VERSION ""

NS_ :

BS_:

BU_: RADAR XXX

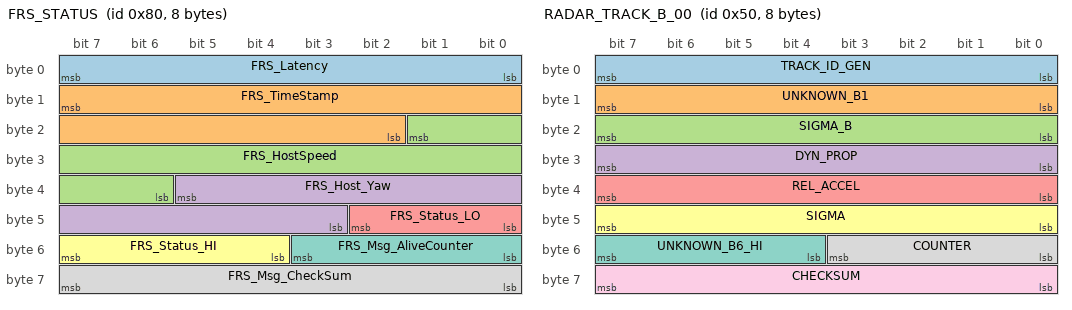
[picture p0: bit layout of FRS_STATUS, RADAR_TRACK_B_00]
BO_ 128 FRS_STATUS: 8 RADAR
 SG_ FRS_Latency : 7|8@0+ (0.5,0) [0|127] "ms" XXX
 SG_ FRS_TimeStamp : 15|14@0+ (1.0077,0) [0|16510] "s" XXX
 SG_ FRS_HostSpeed : 17|12@0+ (0.0243,-19.3) [0|80] "m/s" XXX
 SG_ FRS_Host_Yaw : 37|11@0+ (0.1,-102.4) [-102.4|102.3] "deg/s" XXX
 SG_ FRS_Status_LO : 42|3@0+ (1,0) [0|7] "" XXX
 SG_ FRS_Status_HI : 55|4@0+ (1,0) [0|15] "" XXX
 SG_ FRS_Msg_AliveCounter : 51|4@0+ (1,0) [0|15] "" XXX
 SG_ FRS_Msg_CheckSum : 63|8@0+ (1,0) [0|255] "" XXX

BO_ 32 RADAR_TRACK_A_00: 8 RADAR
 SG_ REL_SPEED : 7|8@0+ (0.7874,-100.47) [-100.5|99.9] "m/s" XXX
 SG_ UNKNOWN_B1 : 15|8@0+ (1,0) [0|255] "" XXX
 SG_ UNKNOWN_B2 : 23|8@0+ (1,0) [0|255] "" XXX
 SG_ LAT_POS : 12|13@0+ (0.015625,-64) [-64|64] "m" XXX
 SG_ DISTANCE : 31|16@0+ (0.00382813,-3.4) [0|247] "m" XXX
 SG_ LAT_SPEED : 47|8@0+ (0.7874,-100.79) [-100.8|99.6] "m/s" XXX
 SG_ UNKNOWN_B6_HI : 55|4@0+ (1,0) [0|15] "" XXX
 SG_ COUNTER : 51|4@0+ (1,0) [0|15] "" XXX
 SG_ CHECKSUM : 63|8@0+ (1,0) [0|255] "" XXX

BO_ 33 RADAR_TRACK_A_01: 8 RADAR
 SG_ REL_SPEED : 7|8@0+ (0.7874,-100.47) [-100.5|99.9] "m/s" XXX
 SG_ UNKNOWN_B1 : 15|8@0+ (1,0) [0|255] "" XXX
 SG_ UNKNOWN_B2 : 23|8@0+ (1,0) [0|255] "" XXX
 SG_ LAT_POS : 12|13@0+ (0.015625,-64) [-64|64] "m" XXX
 SG_ DISTANCE : 31|16@0+ (0.00382813,-3.4) [0|247] "m" XXX
 SG_ LAT_SPEED : 47|8@0+ (0.7874,-100.79) [-100.8|99.6] "m/s" XXX
 SG_ UNKNOWN_B6_HI : 55|4@0+ (1,0) [0|15] "" XXX
 SG_ COUNTER : 51|4@0+ (1,0) [0|15] "" XXX
 SG_ CHECKSUM : 63|8@0+ (1,0) [0|255] "" XXX

BO_ 34 RADAR_TRACK_A_02: 8 RADAR
 SG_ REL_SPEED : 7|8@0+ (0.7874,-100.47) [-100.5|99.9] "m/s" XXX
 SG_ UNKNOWN_B1 : 15|8@0+ (1,0) [0|255] "" XXX
 SG_ UNKNOWN_B2 : 23|8@0+ (1,0) [0|255] "" XXX
 SG_ LAT_POS : 12|13@0+ (0.015625,-64) [-64|64] "m" XXX
 SG_ DISTANCE : 31|16@0+ (0.00382813,-3.4) [0|247] "m" XXX
 SG_ LAT_SPEED : 47|8@0+ (0.7874,-100.79) [-100.8|99.6] "m/s" XXX
 SG_ UNKNOWN_B6_HI : 55|4@0+ (1,0) [0|15] "" XXX
 SG_ COUNTER : 51|4@0+ (1,0) [0|15] "" XXX
 SG_ CHECKSUM : 63|8@0+ (1,0) [0|255] "" XXX

BO_ 35 RADAR_TRACK_A_03: 8 RADAR
 SG_ REL_SPEED : 7|8@0+ (0.7874,-100.47) [-100.5|99.9] "m/s" XXX
 SG_ UNKNOWN_B1 : 15|8@0+ (1,0) [0|255] "" XXX
 SG_ UNKNOWN_B2 : 23|8@0+ (1,0) [0|255] "" XXX
 SG_ LAT_POS : 12|13@0+ (0.015625,-64) [-64|64] "m" XXX
 SG_ DISTANCE : 31|16@0+ (0.00382813,-3.4) [0|247] "m" XXX
 SG_ LAT_SPEED : 47|8@0+ (0.7874,-100.79) [-100.8|99.6] "m/s" XXX
 SG_ UNKNOWN_B6_HI : 55|4@0+ (1,0) [0|15] "" XXX
 SG_ COUNTER : 51|4@0+ (1,0) [0|15] "" XXX
 SG_ CHECKSUM : 63|8@0+ (1,0) [0|255] "" XXX

BO_ 36 RADAR_TRACK_A_04: 8 RADAR
 SG_ REL_SPEED : 7|8@0+ (0.7874,-100.47) [-100.5|99.9] "m/s" XXX
 SG_ UNKNOWN_B1 : 15|8@0+ (1,0) [0|255] "" XXX
 SG_ UNKNOWN_B2 : 23|8@0+ (1,0) [0|255] "" XXX
 SG_ LAT_POS : 12|13@0+ (0.015625,-64) [-64|64] "m" XXX
 SG_ DISTANCE : 31|16@0+ (0.00382813,-3.4) [0|247] "m" XXX
 SG_ LAT_SPEED : 47|8@0+ (0.7874,-100.79) [-100.8|99.6] "m/s" XXX
 SG_ UNKNOWN_B6_HI : 55|4@0+ (1,0) [0|15] "" XXX
 SG_ COUNTER : 51|4@0+ (1,0) [0|15] "" XXX
 SG_ CHECKSUM : 63|8@0+ (1,0) [0|255] "" XXX

BO_ 37 RADAR_TRACK_A_05: 8 RADAR
 SG_ REL_SPEED : 7|8@0+ (0.7874,-100.47) [-100.5|99.9] "m/s" XXX
 SG_ UNKNOWN_B1 : 15|8@0+ (1,0) [0|255] "" XXX
 SG_ UNKNOWN_B2 : 23|8@0+ (1,0) [0|255] "" XXX
 SG_ LAT_POS : 12|13@0+ (0.015625,-64) [-64|64] "m" XXX
 SG_ DISTANCE : 31|16@0+ (0.00382813,-3.4) [0|247] "m" XXX
 SG_ LAT_SPEED : 47|8@0+ (0.7874,-100.79) [-100.8|99.6] "m/s" XXX
 SG_ UNKNOWN_B6_HI : 55|4@0+ (1,0) [0|15] "" XXX
 SG_ COUNTER : 51|4@0+ (1,0) [0|15] "" XXX
 SG_ CHECKSUM : 63|8@0+ (1,0) [0|255] "" XXX

BO_ 38 RADAR_TRACK_A_06: 8 RADAR
 SG_ REL_SPEED : 7|8@0+ (0.7874,-100.47) [-100.5|99.9] "m/s" XXX
 SG_ UNKNOWN_B1 : 15|8@0+ (1,0) [0|255] "" XXX
 SG_ UNKNOWN_B2 : 23|8@0+ (1,0) [0|255] "" XXX
 SG_ LAT_POS : 12|13@0+ (0.015625,-64) [-64|64] "m" XXX
 SG_ DISTANCE : 31|16@0+ (0.00382813,-3.4) [0|247] "m" XXX
 SG_ LAT_SPEED : 47|8@0+ (0.7874,-100.79) [-100.8|99.6] "m/s" XXX
 SG_ UNKNOWN_B6_HI : 55|4@0+ (1,0) [0|15] "" XXX
 SG_ COUNTER : 51|4@0+ (1,0) [0|15] "" XXX
 SG_ CHECKSUM : 63|8@0+ (1,0) [0|255] "" XXX

BO_ 39 RADAR_TRACK_A_07: 8 RADAR
 SG_ REL_SPEED : 7|8@0+ (0.7874,-100.47) [-100.5|99.9] "m/s" XXX
 SG_ UNKNOWN_B1 : 15|8@0+ (1,0) [0|255] "" XXX
 SG_ UNKNOWN_B2 : 23|8@0+ (1,0) [0|255] "" XXX
 SG_ LAT_POS : 12|13@0+ (0.015625,-64) [-64|64] "m" XXX
 SG_ DISTANCE : 31|16@0+ (0.00382813,-3.4) [0|247] "m" XXX
 SG_ LAT_SPEED : 47|8@0+ (0.7874,-100.79) [-100.8|99.6] "m/s" XXX
 SG_ UNKNOWN_B6_HI : 55|4@0+ (1,0) [0|15] "" XXX
 SG_ COUNTER : 51|4@0+ (1,0) [0|15] "" XXX
 SG_ CHECKSUM : 63|8@0+ (1,0) [0|255] "" XXX

BO_ 40 RADAR_TRACK_A_08: 8 RADAR
 SG_ REL_SPEED : 7|8@0+ (0.7874,-100.47) [-100.5|99.9] "m/s" XXX
 SG_ UNKNOWN_B1 : 15|8@0+ (1,0) [0|255] "" XXX
 SG_ UNKNOWN_B2 : 23|8@0+ (1,0) [0|255] "" XXX
 SG_ LAT_POS : 12|13@0+ (0.015625,-64) [-64|64] "m" XXX
 SG_ DISTANCE : 31|16@0+ (0.00382813,-3.4) [0|247] "m" XXX
 SG_ LAT_SPEED : 47|8@0+ (0.7874,-100.79) [-100.8|99.6] "m/s" XXX
 SG_ UNKNOWN_B6_HI : 55|4@0+ (1,0) [0|15] "" XXX
 SG_ COUNTER : 51|4@0+ (1,0) [0|15] "" XXX
 SG_ CHECKSUM : 63|8@0+ (1,0) [0|255] "" XXX

BO_ 41 RADAR_TRACK_A_09: 8 RADAR
 SG_ REL_SPEED : 7|8@0+ (0.7874,-100.47) [-100.5|99.9] "m/s" XXX
 SG_ UNKNOWN_B1 : 15|8@0+ (1,0) [0|255] "" XXX
 SG_ UNKNOWN_B2 : 23|8@0+ (1,0) [0|255] "" XXX
 SG_ LAT_POS : 12|13@0+ (0.015625,-64) [-64|64] "m" XXX
 SG_ DISTANCE : 31|16@0+ (0.00382813,-3.4) [0|247] "m" XXX
 SG_ LAT_SPEED : 47|8@0+ (0.7874,-100.79) [-100.8|99.6] "m/s" XXX
 SG_ UNKNOWN_B6_HI : 55|4@0+ (1,0) [0|15] "" XXX
 SG_ COUNTER : 51|4@0+ (1,0) [0|15] "" XXX
 SG_ CHECKSUM : 63|8@0+ (1,0) [0|255] "" XXX

BO_ 42 RADAR_TRACK_A_10: 8 RADAR
 SG_ REL_SPEED : 7|8@0+ (0.7874,-100.47) [-100.5|99.9] "m/s" XXX
 SG_ UNKNOWN_B1 : 15|8@0+ (1,0) [0|255] "" XXX
 SG_ UNKNOWN_B2 : 23|8@0+ (1,0) [0|255] "" XXX
 SG_ LAT_POS : 12|13@0+ (0.015625,-64) [-64|64] "m" XXX
 SG_ DISTANCE : 31|16@0+ (0.00382813,-3.4) [0|247] "m" XXX
 SG_ LAT_SPEED : 47|8@0+ (0.7874,-100.79) [-100.8|99.6] "m/s" XXX
 SG_ UNKNOWN_B6_HI : 55|4@0+ (1,0) [0|15] "" XXX
 SG_ COUNTER : 51|4@0+ (1,0) [0|15] "" XXX
 SG_ CHECKSUM : 63|8@0+ (1,0) [0|255] "" XXX

BO_ 43 RADAR_TRACK_A_11: 8 RADAR
 SG_ REL_SPEED : 7|8@0+ (0.7874,-100.47) [-100.5|99.9] "m/s" XXX
 SG_ UNKNOWN_B1 : 15|8@0+ (1,0) [0|255] "" XXX
 SG_ UNKNOWN_B2 : 23|8@0+ (1,0) [0|255] "" XXX
 SG_ LAT_POS : 12|13@0+ (0.015625,-64) [-64|64] "m" XXX
 SG_ DISTANCE : 31|16@0+ (0.00382813,-3.4) [0|247] "m" XXX
 SG_ LAT_SPEED : 47|8@0+ (0.7874,-100.79) [-100.8|99.6] "m/s" XXX
 SG_ UNKNOWN_B6_HI : 55|4@0+ (1,0) [0|15] "" XXX
 SG_ COUNTER : 51|4@0+ (1,0) [0|15] "" XXX
 SG_ CHECKSUM : 63|8@0+ (1,0) [0|255] "" XXX

BO_ 44 RADAR_TRACK_A_12: 8 RADAR
 SG_ REL_SPEED : 7|8@0+ (0.7874,-100.47) [-100.5|99.9] "m/s" XXX
 SG_ UNKNOWN_B1 : 15|8@0+ (1,0) [0|255] "" XXX
 SG_ UNKNOWN_B2 : 23|8@0+ (1,0) [0|255] "" XXX
 SG_ LAT_POS : 12|13@0+ (0.015625,-64) [-64|64] "m" XXX
 SG_ DISTANCE : 31|16@0+ (0.00382813,-3.4) [0|247] "m" XXX
 SG_ LAT_SPEED : 47|8@0+ (0.7874,-100.79) [-100.8|99.6] "m/s" XXX
 SG_ UNKNOWN_B6_HI : 55|4@0+ (1,0) [0|15] "" XXX
 SG_ COUNTER : 51|4@0+ (1,0) [0|15] "" XXX
 SG_ CHECKSUM : 63|8@0+ (1,0) [0|255] "" XXX

BO_ 45 RADAR_TRACK_A_13: 8 RADAR
 SG_ REL_SPEED : 7|8@0+ (0.7874,-100.47) [-100.5|99.9] "m/s" XXX
 SG_ UNKNOWN_B1 : 15|8@0+ (1,0) [0|255] "" XXX
 SG_ UNKNOWN_B2 : 23|8@0+ (1,0) [0|255] "" XXX
 SG_ LAT_POS : 12|13@0+ (0.015625,-64) [-64|64] "m" XXX
 SG_ DISTANCE : 31|16@0+ (0.00382813,-3.4) [0|247] "m" XXX
 SG_ LAT_SPEED : 47|8@0+ (0.7874,-100.79) [-100.8|99.6] "m/s" XXX
 SG_ UNKNOWN_B6_HI : 55|4@0+ (1,0) [0|15] "" XXX
 SG_ COUNTER : 51|4@0+ (1,0) [0|15] "" XXX
 SG_ CHECKSUM : 63|8@0+ (1,0) [0|255] "" XXX

BO_ 46 RADAR_TRACK_A_14: 8 RADAR
 SG_ REL_SPEED : 7|8@0+ (0.7874,-100.47) [-100.5|99.9] "m/s" XXX
 SG_ UNKNOWN_B1 : 15|8@0+ (1,0) [0|255] "" XXX
 SG_ UNKNOWN_B2 : 23|8@0+ (1,0) [0|255] "" XXX
 SG_ LAT_POS : 12|13@0+ (0.015625,-64) [-64|64] "m" XXX
 SG_ DISTANCE : 31|16@0+ (0.00382813,-3.4) [0|247] "m" XXX
 SG_ LAT_SPEED : 47|8@0+ (0.7874,-100.79) [-100.8|99.6] "m/s" XXX
 SG_ UNKNOWN_B6_HI : 55|4@0+ (1,0) [0|15] "" XXX
 SG_ COUNTER : 51|4@0+ (1,0) [0|15] "" XXX
 SG_ CHECKSUM : 63|8@0+ (1,0) [0|255] "" XXX

BO_ 47 RADAR_TRACK_A_15: 8 RADAR
 SG_ REL_SPEED : 7|8@0+ (0.7874,-100.47) [-100.5|99.9] "m/s" XXX
 SG_ UNKNOWN_B1 : 15|8@0+ (1,0) [0|255] "" XXX
 SG_ UNKNOWN_B2 : 23|8@0+ (1,0) [0|255] "" XXX
 SG_ LAT_POS : 12|13@0+ (0.015625,-64) [-64|64] "m" XXX
 SG_ DISTANCE : 31|16@0+ (0.00382813,-3.4) [0|247] "m" XXX
 SG_ LAT_SPEED : 47|8@0+ (0.7874,-100.79) [-100.8|99.6] "m/s" XXX
 SG_ UNKNOWN_B6_HI : 55|4@0+ (1,0) [0|15] "" XXX
 SG_ COUNTER : 51|4@0+ (1,0) [0|15] "" XXX
 SG_ CHECKSUM : 63|8@0+ (1,0) [0|255] "" XXX

BO_ 48 RADAR_TRACK_A_16: 8 RADAR
 SG_ REL_SPEED : 7|8@0+ (0.7874,-100.47) [-100.5|99.9] "m/s" XXX
 SG_ UNKNOWN_B1 : 15|8@0+ (1,0) [0|255] "" XXX
 SG_ UNKNOWN_B2 : 23|8@0+ (1,0) [0|255] "" XXX
 SG_ LAT_POS : 12|13@0+ (0.015625,-64) [-64|64] "m" XXX
 SG_ DISTANCE : 31|16@0+ (0.00382813,-3.4) [0|247] "m" XXX
 SG_ LAT_SPEED : 47|8@0+ (0.7874,-100.79) [-100.8|99.6] "m/s" XXX
 SG_ UNKNOWN_B6_HI : 55|4@0+ (1,0) [0|15] "" XXX
 SG_ COUNTER : 51|4@0+ (1,0) [0|15] "" XXX
 SG_ CHECKSUM : 63|8@0+ (1,0) [0|255] "" XXX

BO_ 49 RADAR_TRACK_A_17: 8 RADAR
 SG_ REL_SPEED : 7|8@0+ (0.7874,-100.47) [-100.5|99.9] "m/s" XXX
 SG_ UNKNOWN_B1 : 15|8@0+ (1,0) [0|255] "" XXX
 SG_ UNKNOWN_B2 : 23|8@0+ (1,0) [0|255] "" XXX
 SG_ LAT_POS : 12|13@0+ (0.015625,-64) [-64|64] "m" XXX
 SG_ DISTANCE : 31|16@0+ (0.00382813,-3.4) [0|247] "m" XXX
 SG_ LAT_SPEED : 47|8@0+ (0.7874,-100.79) [-100.8|99.6] "m/s" XXX
 SG_ UNKNOWN_B6_HI : 55|4@0+ (1,0) [0|15] "" XXX
 SG_ COUNTER : 51|4@0+ (1,0) [0|15] "" XXX
 SG_ CHECKSUM : 63|8@0+ (1,0) [0|255] "" XXX

BO_ 50 RADAR_TRACK_A_18: 8 RADAR
 SG_ REL_SPEED : 7|8@0+ (0.7874,-100.47) [-100.5|99.9] "m/s" XXX
 SG_ UNKNOWN_B1 : 15|8@0+ (1,0) [0|255] "" XXX
 SG_ UNKNOWN_B2 : 23|8@0+ (1,0) [0|255] "" XXX
 SG_ LAT_POS : 12|13@0+ (0.015625,-64) [-64|64] "m" XXX
 SG_ DISTANCE : 31|16@0+ (0.00382813,-3.4) [0|247] "m" XXX
 SG_ LAT_SPEED : 47|8@0+ (0.7874,-100.79) [-100.8|99.6] "m/s" XXX
 SG_ UNKNOWN_B6_HI : 55|4@0+ (1,0) [0|15] "" XXX
 SG_ COUNTER : 51|4@0+ (1,0) [0|15] "" XXX
 SG_ CHECKSUM : 63|8@0+ (1,0) [0|255] "" XXX

BO_ 51 RADAR_TRACK_A_19: 8 RADAR
 SG_ REL_SPEED : 7|8@0+ (0.7874,-100.47) [-100.5|99.9] "m/s" XXX
 SG_ UNKNOWN_B1 : 15|8@0+ (1,0) [0|255] "" XXX
 SG_ UNKNOWN_B2 : 23|8@0+ (1,0) [0|255] "" XXX
 SG_ LAT_POS : 12|13@0+ (0.015625,-64) [-64|64] "m" XXX
 SG_ DISTANCE : 31|16@0+ (0.00382813,-3.4) [0|247] "m" XXX
 SG_ LAT_SPEED : 47|8@0+ (0.7874,-100.79) [-100.8|99.6] "m/s" XXX
 SG_ UNKNOWN_B6_HI : 55|4@0+ (1,0) [0|15] "" XXX
 SG_ COUNTER : 51|4@0+ (1,0) [0|15] "" XXX
 SG_ CHECKSUM : 63|8@0+ (1,0) [0|255] "" XXX

BO_ 52 RADAR_TRACK_A_20: 8 RADAR
 SG_ REL_SPEED : 7|8@0+ (0.7874,-100.47) [-100.5|99.9] "m/s" XXX
 SG_ UNKNOWN_B1 : 15|8@0+ (1,0) [0|255] "" XXX
 SG_ UNKNOWN_B2 : 23|8@0+ (1,0) [0|255] "" XXX
 SG_ LAT_POS : 12|13@0+ (0.015625,-64) [-64|64] "m" XXX
 SG_ DISTANCE : 31|16@0+ (0.00382813,-3.4) [0|247] "m" XXX
 SG_ LAT_SPEED : 47|8@0+ (0.7874,-100.79) [-100.8|99.6] "m/s" XXX
 SG_ UNKNOWN_B6_HI : 55|4@0+ (1,0) [0|15] "" XXX
 SG_ COUNTER : 51|4@0+ (1,0) [0|15] "" XXX
 SG_ CHECKSUM : 63|8@0+ (1,0) [0|255] "" XXX

BO_ 53 RADAR_TRACK_A_21: 8 RADAR
 SG_ REL_SPEED : 7|8@0+ (0.7874,-100.47) [-100.5|99.9] "m/s" XXX
 SG_ UNKNOWN_B1 : 15|8@0+ (1,0) [0|255] "" XXX
 SG_ UNKNOWN_B2 : 23|8@0+ (1,0) [0|255] "" XXX
 SG_ LAT_POS : 12|13@0+ (0.015625,-64) [-64|64] "m" XXX
 SG_ DISTANCE : 31|16@0+ (0.00382813,-3.4) [0|247] "m" XXX
 SG_ LAT_SPEED : 47|8@0+ (0.7874,-100.79) [-100.8|99.6] "m/s" XXX
 SG_ UNKNOWN_B6_HI : 55|4@0+ (1,0) [0|15] "" XXX
 SG_ COUNTER : 51|4@0+ (1,0) [0|15] "" XXX
 SG_ CHECKSUM : 63|8@0+ (1,0) [0|255] "" XXX

BO_ 54 RADAR_TRACK_A_22: 8 RADAR
 SG_ REL_SPEED : 7|8@0+ (0.7874,-100.47) [-100.5|99.9] "m/s" XXX
 SG_ UNKNOWN_B1 : 15|8@0+ (1,0) [0|255] "" XXX
 SG_ UNKNOWN_B2 : 23|8@0+ (1,0) [0|255] "" XXX
 SG_ LAT_POS : 12|13@0+ (0.015625,-64) [-64|64] "m" XXX
 SG_ DISTANCE : 31|16@0+ (0.00382813,-3.4) [0|247] "m" XXX
 SG_ LAT_SPEED : 47|8@0+ (0.7874,-100.79) [-100.8|99.6] "m/s" XXX
 SG_ UNKNOWN_B6_HI : 55|4@0+ (1,0) [0|15] "" XXX
 SG_ COUNTER : 51|4@0+ (1,0) [0|15] "" XXX
 SG_ CHECKSUM : 63|8@0+ (1,0) [0|255] "" XXX

BO_ 55 RADAR_TRACK_A_23: 8 RADAR
 SG_ REL_SPEED : 7|8@0+ (0.7874,-100.47) [-100.5|99.9] "m/s" XXX
 SG_ UNKNOWN_B1 : 15|8@0+ (1,0) [0|255] "" XXX
 SG_ UNKNOWN_B2 : 23|8@0+ (1,0) [0|255] "" XXX
 SG_ LAT_POS : 12|13@0+ (0.015625,-64) [-64|64] "m" XXX
 SG_ DISTANCE : 31|16@0+ (0.00382813,-3.4) [0|247] "m" XXX
 SG_ LAT_SPEED : 47|8@0+ (0.7874,-100.79) [-100.8|99.6] "m/s" XXX
 SG_ UNKNOWN_B6_HI : 55|4@0+ (1,0) [0|15] "" XXX
 SG_ COUNTER : 51|4@0+ (1,0) [0|15] "" XXX
 SG_ CHECKSUM : 63|8@0+ (1,0) [0|255] "" XXX

BO_ 56 RADAR_TRACK_A_24: 8 RADAR
 SG_ REL_SPEED : 7|8@0+ (0.7874,-100.47) [-100.5|99.9] "m/s" XXX
 SG_ UNKNOWN_B1 : 15|8@0+ (1,0) [0|255] "" XXX
 SG_ UNKNOWN_B2 : 23|8@0+ (1,0) [0|255] "" XXX
 SG_ LAT_POS : 12|13@0+ (0.015625,-64) [-64|64] "m" XXX
 SG_ DISTANCE : 31|16@0+ (0.00382813,-3.4) [0|247] "m" XXX
 SG_ LAT_SPEED : 47|8@0+ (0.7874,-100.79) [-100.8|99.6] "m/s" XXX
 SG_ UNKNOWN_B6_HI : 55|4@0+ (1,0) [0|15] "" XXX
 SG_ COUNTER : 51|4@0+ (1,0) [0|15] "" XXX
 SG_ CHECKSUM : 63|8@0+ (1,0) [0|255] "" XXX

BO_ 57 RADAR_TRACK_A_25: 8 RADAR
 SG_ REL_SPEED : 7|8@0+ (0.7874,-100.47) [-100.5|99.9] "m/s" XXX
 SG_ UNKNOWN_B1 : 15|8@0+ (1,0) [0|255] "" XXX
 SG_ UNKNOWN_B2 : 23|8@0+ (1,0) [0|255] "" XXX
 SG_ LAT_POS : 12|13@0+ (0.015625,-64) [-64|64] "m" XXX
 SG_ DISTANCE : 31|16@0+ (0.00382813,-3.4) [0|247] "m" XXX
 SG_ LAT_SPEED : 47|8@0+ (0.7874,-100.79) [-100.8|99.6] "m/s" XXX
 SG_ UNKNOWN_B6_HI : 55|4@0+ (1,0) [0|15] "" XXX
 SG_ COUNTER : 51|4@0+ (1,0) [0|15] "" XXX
 SG_ CHECKSUM : 63|8@0+ (1,0) [0|255] "" XXX

BO_ 58 RADAR_TRACK_A_26: 8 RADAR
 SG_ REL_SPEED : 7|8@0+ (0.7874,-100.47) [-100.5|99.9] "m/s" XXX
 SG_ UNKNOWN_B1 : 15|8@0+ (1,0) [0|255] "" XXX
 SG_ UNKNOWN_B2 : 23|8@0+ (1,0) [0|255] "" XXX
 SG_ LAT_POS : 12|13@0+ (0.015625,-64) [-64|64] "m" XXX
 SG_ DISTANCE : 31|16@0+ (0.00382813,-3.4) [0|247] "m" XXX
 SG_ LAT_SPEED : 47|8@0+ (0.7874,-100.79) [-100.8|99.6] "m/s" XXX
 SG_ UNKNOWN_B6_HI : 55|4@0+ (1,0) [0|15] "" XXX
 SG_ COUNTER : 51|4@0+ (1,0) [0|15] "" XXX
 SG_ CHECKSUM : 63|8@0+ (1,0) [0|255] "" XXX

BO_ 59 RADAR_TRACK_A_27: 8 RADAR
 SG_ REL_SPEED : 7|8@0+ (0.7874,-100.47) [-100.5|99.9] "m/s" XXX
 SG_ UNKNOWN_B1 : 15|8@0+ (1,0) [0|255] "" XXX
 SG_ UNKNOWN_B2 : 23|8@0+ (1,0) [0|255] "" XXX
 SG_ LAT_POS : 12|13@0+ (0.015625,-64) [-64|64] "m" XXX
 SG_ DISTANCE : 31|16@0+ (0.00382813,-3.4) [0|247] "m" XXX
 SG_ LAT_SPEED : 47|8@0+ (0.7874,-100.79) [-100.8|99.6] "m/s" XXX
 SG_ UNKNOWN_B6_HI : 55|4@0+ (1,0) [0|15] "" XXX
 SG_ COUNTER : 51|4@0+ (1,0) [0|15] "" XXX
 SG_ CHECKSUM : 63|8@0+ (1,0) [0|255] "" XXX

BO_ 60 RADAR_TRACK_A_28: 8 RADAR
 SG_ REL_SPEED : 7|8@0+ (0.7874,-100.47) [-100.5|99.9] "m/s" XXX
 SG_ UNKNOWN_B1 : 15|8@0+ (1,0) [0|255] "" XXX
 SG_ UNKNOWN_B2 : 23|8@0+ (1,0) [0|255] "" XXX
 SG_ LAT_POS : 12|13@0+ (0.015625,-64) [-64|64] "m" XXX
 SG_ DISTANCE : 31|16@0+ (0.00382813,-3.4) [0|247] "m" XXX
 SG_ LAT_SPEED : 47|8@0+ (0.7874,-100.79) [-100.8|99.6] "m/s" XXX
 SG_ UNKNOWN_B6_HI : 55|4@0+ (1,0) [0|15] "" XXX
 SG_ COUNTER : 51|4@0+ (1,0) [0|15] "" XXX
 SG_ CHECKSUM : 63|8@0+ (1,0) [0|255] "" XXX

BO_ 61 RADAR_TRACK_A_29: 8 RADAR
 SG_ REL_SPEED : 7|8@0+ (0.7874,-100.47) [-100.5|99.9] "m/s" XXX
 SG_ UNKNOWN_B1 : 15|8@0+ (1,0) [0|255] "" XXX
 SG_ UNKNOWN_B2 : 23|8@0+ (1,0) [0|255] "" XXX
 SG_ LAT_POS : 12|13@0+ (0.015625,-64) [-64|64] "m" XXX
 SG_ DISTANCE : 31|16@0+ (0.00382813,-3.4) [0|247] "m" XXX
 SG_ LAT_SPEED : 47|8@0+ (0.7874,-100.79) [-100.8|99.6] "m/s" XXX
 SG_ UNKNOWN_B6_HI : 55|4@0+ (1,0) [0|15] "" XXX
 SG_ COUNTER : 51|4@0+ (1,0) [0|15] "" XXX
 SG_ CHECKSUM : 63|8@0+ (1,0) [0|255] "" XXX

BO_ 62 RADAR_TRACK_A_30: 8 RADAR
 SG_ REL_SPEED : 7|8@0+ (0.7874,-100.47) [-100.5|99.9] "m/s" XXX
 SG_ UNKNOWN_B1 : 15|8@0+ (1,0) [0|255] "" XXX
 SG_ UNKNOWN_B2 : 23|8@0+ (1,0) [0|255] "" XXX
 SG_ LAT_POS : 12|13@0+ (0.015625,-64) [-64|64] "m" XXX
 SG_ DISTANCE : 31|16@0+ (0.00382813,-3.4) [0|247] "m" XXX
 SG_ LAT_SPEED : 47|8@0+ (0.7874,-100.79) [-100.8|99.6] "m/s" XXX
 SG_ UNKNOWN_B6_HI : 55|4@0+ (1,0) [0|15] "" XXX
 SG_ COUNTER : 51|4@0+ (1,0) [0|15] "" XXX
 SG_ CHECKSUM : 63|8@0+ (1,0) [0|255] "" XXX

BO_ 63 RADAR_TRACK_A_31: 8 RADAR
 SG_ REL_SPEED : 7|8@0+ (0.7874,-100.47) [-100.5|99.9] "m/s" XXX
 SG_ UNKNOWN_B1 : 15|8@0+ (1,0) [0|255] "" XXX
 SG_ UNKNOWN_B2 : 23|8@0+ (1,0) [0|255] "" XXX
 SG_ LAT_POS : 12|13@0+ (0.015625,-64) [-64|64] "m" XXX
 SG_ DISTANCE : 31|16@0+ (0.00382813,-3.4) [0|247] "m" XXX
 SG_ LAT_SPEED : 47|8@0+ (0.7874,-100.79) [-100.8|99.6] "m/s" XXX
 SG_ UNKNOWN_B6_HI : 55|4@0+ (1,0) [0|15] "" XXX
 SG_ COUNTER : 51|4@0+ (1,0) [0|15] "" XXX
 SG_ CHECKSUM : 63|8@0+ (1,0) [0|255] "" XXX

BO_ 64 RADAR_TRACK_A_32: 8 RADAR
 SG_ REL_SPEED : 7|8@0+ (0.7874,-100.47) [-100.5|99.9] "m/s" XXX
 SG_ UNKNOWN_B1 : 15|8@0+ (1,0) [0|255] "" XXX
 SG_ UNKNOWN_B2 : 23|8@0+ (1,0) [0|255] "" XXX
 SG_ LAT_POS : 12|13@0+ (0.015625,-64) [-64|64] "m" XXX
 SG_ DISTANCE : 31|16@0+ (0.00382813,-3.4) [0|247] "m" XXX
 SG_ LAT_SPEED : 47|8@0+ (0.7874,-100.79) [-100.8|99.6] "m/s" XXX
 SG_ UNKNOWN_B6_HI : 55|4@0+ (1,0) [0|15] "" XXX
 SG_ COUNTER : 51|4@0+ (1,0) [0|15] "" XXX
 SG_ CHECKSUM : 63|8@0+ (1,0) [0|255] "" XXX

BO_ 65 RADAR_TRACK_A_33: 8 RADAR
 SG_ REL_SPEED : 7|8@0+ (0.7874,-100.47) [-100.5|99.9] "m/s" XXX
 SG_ UNKNOWN_B1 : 15|8@0+ (1,0) [0|255] "" XXX
 SG_ UNKNOWN_B2 : 23|8@0+ (1,0) [0|255] "" XXX
 SG_ LAT_POS : 12|13@0+ (0.015625,-64) [-64|64] "m" XXX
 SG_ DISTANCE : 31|16@0+ (0.00382813,-3.4) [0|247] "m" XXX
 SG_ LAT_SPEED : 47|8@0+ (0.7874,-100.79) [-100.8|99.6] "m/s" XXX
 SG_ UNKNOWN_B6_HI : 55|4@0+ (1,0) [0|15] "" XXX
 SG_ COUNTER : 51|4@0+ (1,0) [0|15] "" XXX
 SG_ CHECKSUM : 63|8@0+ (1,0) [0|255] "" XXX

BO_ 66 RADAR_TRACK_A_34: 8 RADAR
 SG_ REL_SPEED : 7|8@0+ (0.7874,-100.47) [-100.5|99.9] "m/s" XXX
 SG_ UNKNOWN_B1 : 15|8@0+ (1,0) [0|255] "" XXX
 SG_ UNKNOWN_B2 : 23|8@0+ (1,0) [0|255] "" XXX
 SG_ LAT_POS : 12|13@0+ (0.015625,-64) [-64|64] "m" XXX
 SG_ DISTANCE : 31|16@0+ (0.00382813,-3.4) [0|247] "m" XXX
 SG_ LAT_SPEED : 47|8@0+ (0.7874,-100.79) [-100.8|99.6] "m/s" XXX
 SG_ UNKNOWN_B6_HI : 55|4@0+ (1,0) [0|15] "" XXX
 SG_ COUNTER : 51|4@0+ (1,0) [0|15] "" XXX
 SG_ CHECKSUM : 63|8@0+ (1,0) [0|255] "" XXX

BO_ 67 RADAR_TRACK_A_35: 8 RADAR
 SG_ REL_SPEED : 7|8@0+ (0.7874,-100.47) [-100.5|99.9] "m/s" XXX
 SG_ UNKNOWN_B1 : 15|8@0+ (1,0) [0|255] "" XXX
 SG_ UNKNOWN_B2 : 23|8@0+ (1,0) [0|255] "" XXX
 SG_ LAT_POS : 12|13@0+ (0.015625,-64) [-64|64] "m" XXX
 SG_ DISTANCE : 31|16@0+ (0.00382813,-3.4) [0|247] "m" XXX
 SG_ LAT_SPEED : 47|8@0+ (0.7874,-100.79) [-100.8|99.6] "m/s" XXX
 SG_ UNKNOWN_B6_HI : 55|4@0+ (1,0) [0|15] "" XXX
 SG_ COUNTER : 51|4@0+ (1,0) [0|15] "" XXX
 SG_ CHECKSUM : 63|8@0+ (1,0) [0|255] "" XXX

BO_ 68 RADAR_TRACK_A_36: 8 RADAR
 SG_ REL_SPEED : 7|8@0+ (0.7874,-100.47) [-100.5|99.9] "m/s" XXX
 SG_ UNKNOWN_B1 : 15|8@0+ (1,0) [0|255] "" XXX
 SG_ UNKNOWN_B2 : 23|8@0+ (1,0) [0|255] "" XXX
 SG_ LAT_POS : 12|13@0+ (0.015625,-64) [-64|64] "m" XXX
 SG_ DISTANCE : 31|16@0+ (0.00382813,-3.4) [0|247] "m" XXX
 SG_ LAT_SPEED : 47|8@0+ (0.7874,-100.79) [-100.8|99.6] "m/s" XXX
 SG_ UNKNOWN_B6_HI : 55|4@0+ (1,0) [0|15] "" XXX
 SG_ COUNTER : 51|4@0+ (1,0) [0|15] "" XXX
 SG_ CHECKSUM : 63|8@0+ (1,0) [0|255] "" XXX

BO_ 69 RADAR_TRACK_A_37: 8 RADAR
 SG_ REL_SPEED : 7|8@0+ (0.7874,-100.47) [-100.5|99.9] "m/s" XXX
 SG_ UNKNOWN_B1 : 15|8@0+ (1,0) [0|255] "" XXX
 SG_ UNKNOWN_B2 : 23|8@0+ (1,0) [0|255] "" XXX
 SG_ LAT_POS : 12|13@0+ (0.015625,-64) [-64|64] "m" XXX
 SG_ DISTANCE : 31|16@0+ (0.00382813,-3.4) [0|247] "m" XXX
 SG_ LAT_SPEED : 47|8@0+ (0.7874,-100.79) [-100.8|99.6] "m/s" XXX
 SG_ UNKNOWN_B6_HI : 55|4@0+ (1,0) [0|15] "" XXX
 SG_ COUNTER : 51|4@0+ (1,0) [0|15] "" XXX
 SG_ CHECKSUM : 63|8@0+ (1,0) [0|255] "" XXX

BO_ 70 RADAR_TRACK_A_38: 8 RADAR
 SG_ REL_SPEED : 7|8@0+ (0.7874,-100.47) [-100.5|99.9] "m/s" XXX
 SG_ UNKNOWN_B1 : 15|8@0+ (1,0) [0|255] "" XXX
 SG_ UNKNOWN_B2 : 23|8@0+ (1,0) [0|255] "" XXX
 SG_ LAT_POS : 12|13@0+ (0.015625,-64) [-64|64] "m" XXX
 SG_ DISTANCE : 31|16@0+ (0.00382813,-3.4) [0|247] "m" XXX
 SG_ LAT_SPEED : 47|8@0+ (0.7874,-100.79) [-100.8|99.6] "m/s" XXX
 SG_ UNKNOWN_B6_HI : 55|4@0+ (1,0) [0|15] "" XXX
 SG_ COUNTER : 51|4@0+ (1,0) [0|15] "" XXX
 SG_ CHECKSUM : 63|8@0+ (1,0) [0|255] "" XXX

BO_ 71 RADAR_TRACK_A_39: 8 RADAR
 SG_ REL_SPEED : 7|8@0+ (0.7874,-100.47) [-100.5|99.9] "m/s" XXX
 SG_ UNKNOWN_B1 : 15|8@0+ (1,0) [0|255] "" XXX
 SG_ UNKNOWN_B2 : 23|8@0+ (1,0) [0|255] "" XXX
 SG_ LAT_POS : 12|13@0+ (0.015625,-64) [-64|64] "m" XXX
 SG_ DISTANCE : 31|16@0+ (0.00382813,-3.4) [0|247] "m" XXX
 SG_ LAT_SPEED : 47|8@0+ (0.7874,-100.79) [-100.8|99.6] "m/s" XXX
 SG_ UNKNOWN_B6_HI : 55|4@0+ (1,0) [0|15] "" XXX
 SG_ COUNTER : 51|4@0+ (1,0) [0|15] "" XXX
 SG_ CHECKSUM : 63|8@0+ (1,0) [0|255] "" XXX

BO_ 80 RADAR_TRACK_B_00: 8 RADAR
 SG_ TRACK_ID_GEN : 7|8@0+ (1,0) [0|255] "" XXX
 SG_ UNKNOWN_B1 : 15|8@0+ (1,0) [0|255] "" XXX
 SG_ SIGMA_B : 23|8@0+ (1,0) [0|255] "" XXX
 SG_ DYN_PROP : 31|8@0+ (1,0) [0|255] "" XXX
 SG_ REL_ACCEL : 39|8@0+ (0.08,-10.24) [-10.24|10.16] "m/s2" XXX
 SG_ SIGMA : 47|8@0+ (1,0) [0|255] "" XXX
 SG_ UNKNOWN_B6_HI : 55|4@0+ (1,0) [0|15] "" XXX
 SG_ COUNTER : 51|4@0+ (1,0) [0|15] "" XXX
 SG_ CHECKSUM : 63|8@0+ (1,0) [0|255] "" XXX

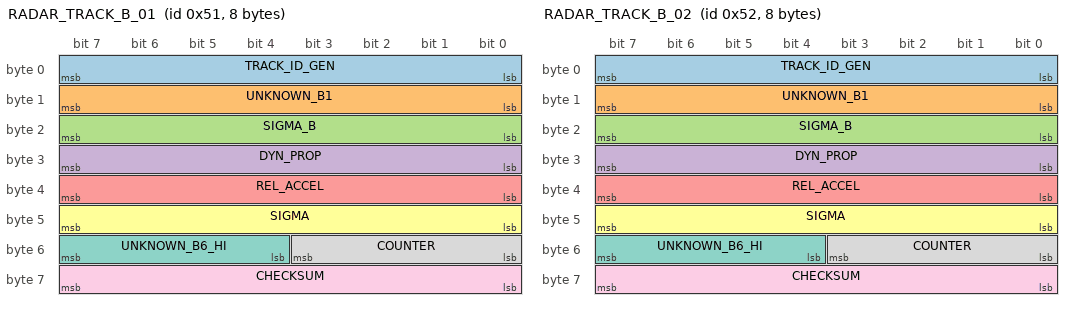
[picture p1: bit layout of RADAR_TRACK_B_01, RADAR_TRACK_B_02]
BO_ 81 RADAR_TRACK_B_01: 8 RADAR
 SG_ TRACK_ID_GEN : 7|8@0+ (1,0) [0|255] "" XXX
 SG_ UNKNOWN_B1 : 15|8@0+ (1,0) [0|255] "" XXX
 SG_ SIGMA_B : 23|8@0+ (1,0) [0|255] "" XXX
 SG_ DYN_PROP : 31|8@0+ (1,0) [0|255] "" XXX
 SG_ REL_ACCEL : 39|8@0+ (0.08,-10.24) [-10.24|10.16] "m/s2" XXX
 SG_ SIGMA : 47|8@0+ (1,0) [0|255] "" XXX
 SG_ UNKNOWN_B6_HI : 55|4@0+ (1,0) [0|15] "" XXX
 SG_ COUNTER : 51|4@0+ (1,0) [0|15] "" XXX
 SG_ CHECKSUM : 63|8@0+ (1,0) [0|255] "" XXX

BO_ 82 RADAR_TRACK_B_02: 8 RADAR
 SG_ TRACK_ID_GEN : 7|8@0+ (1,0) [0|255] "" XXX
 SG_ UNKNOWN_B1 : 15|8@0+ (1,0) [0|255] "" XXX
 SG_ SIGMA_B : 23|8@0+ (1,0) [0|255] "" XXX
 SG_ DYN_PROP : 31|8@0+ (1,0) [0|255] "" XXX
 SG_ REL_ACCEL : 39|8@0+ (0.08,-10.24) [-10.24|10.16] "m/s2" XXX
 SG_ SIGMA : 47|8@0+ (1,0) [0|255] "" XXX
 SG_ UNKNOWN_B6_HI : 55|4@0+ (1,0) [0|15] "" XXX
 SG_ COUNTER : 51|4@0+ (1,0) [0|15] "" XXX
 SG_ CHECKSUM : 63|8@0+ (1,0) [0|255] "" XXX

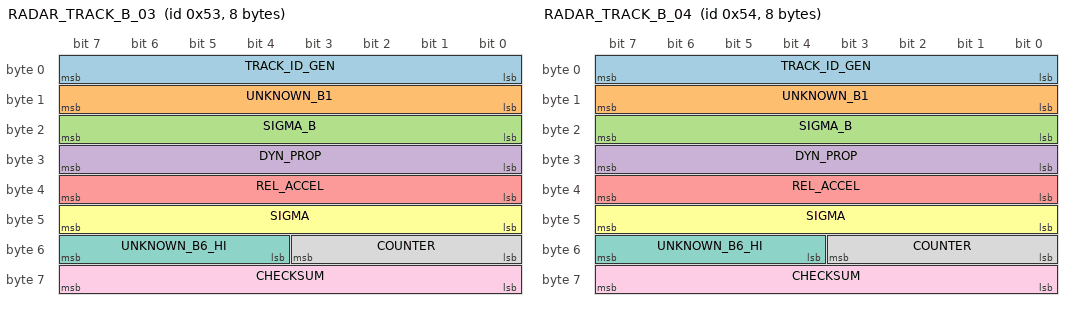
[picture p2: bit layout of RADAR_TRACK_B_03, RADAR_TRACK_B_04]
BO_ 83 RADAR_TRACK_B_03: 8 RADAR
 SG_ TRACK_ID_GEN : 7|8@0+ (1,0) [0|255] "" XXX
 SG_ UNKNOWN_B1 : 15|8@0+ (1,0) [0|255] "" XXX
 SG_ SIGMA_B : 23|8@0+ (1,0) [0|255] "" XXX
 SG_ DYN_PROP : 31|8@0+ (1,0) [0|255] "" XXX
 SG_ REL_ACCEL : 39|8@0+ (0.08,-10.24) [-10.24|10.16] "m/s2" XXX
 SG_ SIGMA : 47|8@0+ (1,0) [0|255] "" XXX
 SG_ UNKNOWN_B6_HI : 55|4@0+ (1,0) [0|15] "" XXX
 SG_ COUNTER : 51|4@0+ (1,0) [0|15] "" XXX
 SG_ CHECKSUM : 63|8@0+ (1,0) [0|255] "" XXX

BO_ 84 RADAR_TRACK_B_04: 8 RADAR
 SG_ TRACK_ID_GEN : 7|8@0+ (1,0) [0|255] "" XXX
 SG_ UNKNOWN_B1 : 15|8@0+ (1,0) [0|255] "" XXX
 SG_ SIGMA_B : 23|8@0+ (1,0) [0|255] "" XXX
 SG_ DYN_PROP : 31|8@0+ (1,0) [0|255] "" XXX
 SG_ REL_ACCEL : 39|8@0+ (0.08,-10.24) [-10.24|10.16] "m/s2" XXX
 SG_ SIGMA : 47|8@0+ (1,0) [0|255] "" XXX
 SG_ UNKNOWN_B6_HI : 55|4@0+ (1,0) [0|15] "" XXX
 SG_ COUNTER : 51|4@0+ (1,0) [0|15] "" XXX
 SG_ CHECKSUM : 63|8@0+ (1,0) [0|255] "" XXX

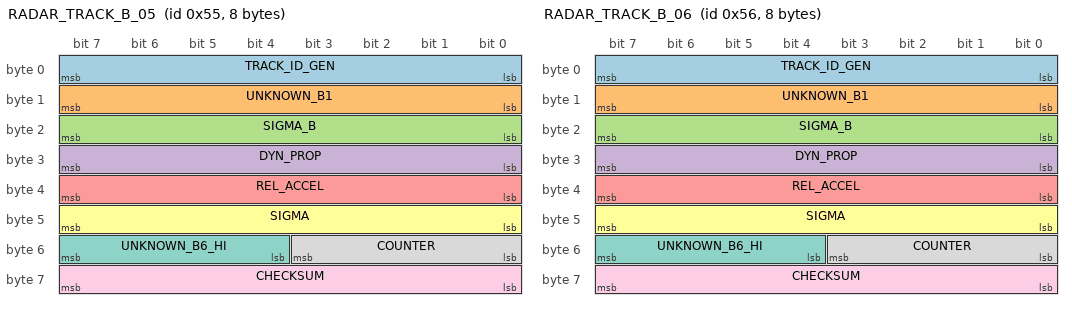
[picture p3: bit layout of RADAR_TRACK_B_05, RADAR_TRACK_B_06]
BO_ 85 RADAR_TRACK_B_05: 8 RADAR
 SG_ TRACK_ID_GEN : 7|8@0+ (1,0) [0|255] "" XXX
 SG_ UNKNOWN_B1 : 15|8@0+ (1,0) [0|255] "" XXX
 SG_ SIGMA_B : 23|8@0+ (1,0) [0|255] "" XXX
 SG_ DYN_PROP : 31|8@0+ (1,0) [0|255] "" XXX
 SG_ REL_ACCEL : 39|8@0+ (0.08,-10.24) [-10.24|10.16] "m/s2" XXX
 SG_ SIGMA : 47|8@0+ (1,0) [0|255] "" XXX
 SG_ UNKNOWN_B6_HI : 55|4@0+ (1,0) [0|15] "" XXX
 SG_ COUNTER : 51|4@0+ (1,0) [0|15] "" XXX
 SG_ CHECKSUM : 63|8@0+ (1,0) [0|255] "" XXX

BO_ 86 RADAR_TRACK_B_06: 8 RADAR
 SG_ TRACK_ID_GEN : 7|8@0+ (1,0) [0|255] "" XXX
 SG_ UNKNOWN_B1 : 15|8@0+ (1,0) [0|255] "" XXX
 SG_ SIGMA_B : 23|8@0+ (1,0) [0|255] "" XXX
 SG_ DYN_PROP : 31|8@0+ (1,0) [0|255] "" XXX
 SG_ REL_ACCEL : 39|8@0+ (0.08,-10.24) [-10.24|10.16] "m/s2" XXX
 SG_ SIGMA : 47|8@0+ (1,0) [0|255] "" XXX
 SG_ UNKNOWN_B6_HI : 55|4@0+ (1,0) [0|15] "" XXX
 SG_ COUNTER : 51|4@0+ (1,0) [0|15] "" XXX
 SG_ CHECKSUM : 63|8@0+ (1,0) [0|255] "" XXX

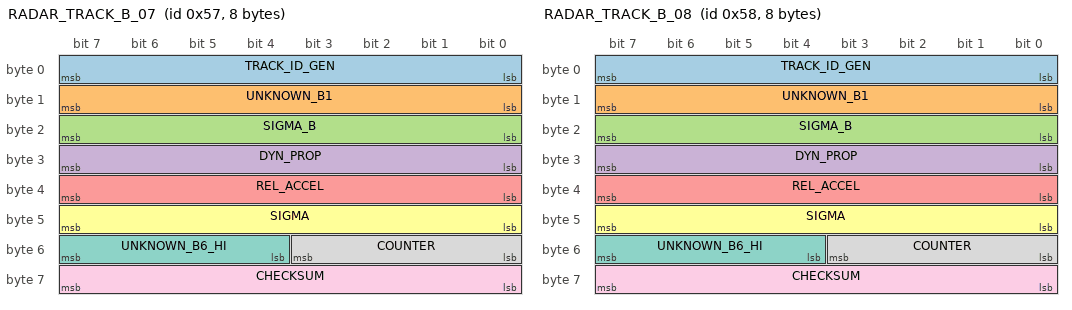
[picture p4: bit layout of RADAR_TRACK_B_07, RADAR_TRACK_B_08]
BO_ 87 RADAR_TRACK_B_07: 8 RADAR
 SG_ TRACK_ID_GEN : 7|8@0+ (1,0) [0|255] "" XXX
 SG_ UNKNOWN_B1 : 15|8@0+ (1,0) [0|255] "" XXX
 SG_ SIGMA_B : 23|8@0+ (1,0) [0|255] "" XXX
 SG_ DYN_PROP : 31|8@0+ (1,0) [0|255] "" XXX
 SG_ REL_ACCEL : 39|8@0+ (0.08,-10.24) [-10.24|10.16] "m/s2" XXX
 SG_ SIGMA : 47|8@0+ (1,0) [0|255] "" XXX
 SG_ UNKNOWN_B6_HI : 55|4@0+ (1,0) [0|15] "" XXX
 SG_ COUNTER : 51|4@0+ (1,0) [0|15] "" XXX
 SG_ CHECKSUM : 63|8@0+ (1,0) [0|255] "" XXX

BO_ 88 RADAR_TRACK_B_08: 8 RADAR
 SG_ TRACK_ID_GEN : 7|8@0+ (1,0) [0|255] "" XXX
 SG_ UNKNOWN_B1 : 15|8@0+ (1,0) [0|255] "" XXX
 SG_ SIGMA_B : 23|8@0+ (1,0) [0|255] "" XXX
 SG_ DYN_PROP : 31|8@0+ (1,0) [0|255] "" XXX
 SG_ REL_ACCEL : 39|8@0+ (0.08,-10.24) [-10.24|10.16] "m/s2" XXX
 SG_ SIGMA : 47|8@0+ (1,0) [0|255] "" XXX
 SG_ UNKNOWN_B6_HI : 55|4@0+ (1,0) [0|15] "" XXX
 SG_ COUNTER : 51|4@0+ (1,0) [0|15] "" XXX
 SG_ CHECKSUM : 63|8@0+ (1,0) [0|255] "" XXX

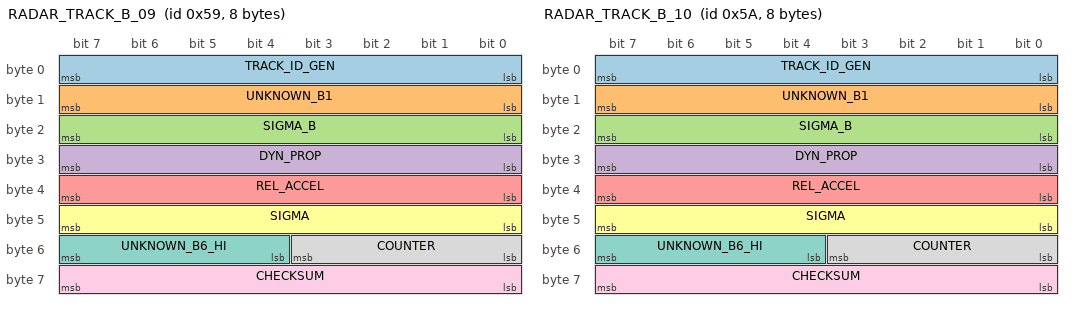
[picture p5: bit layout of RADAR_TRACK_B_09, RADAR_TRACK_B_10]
BO_ 89 RADAR_TRACK_B_09: 8 RADAR
 SG_ TRACK_ID_GEN : 7|8@0+ (1,0) [0|255] "" XXX
 SG_ UNKNOWN_B1 : 15|8@0+ (1,0) [0|255] "" XXX
 SG_ SIGMA_B : 23|8@0+ (1,0) [0|255] "" XXX
 SG_ DYN_PROP : 31|8@0+ (1,0) [0|255] "" XXX
 SG_ REL_ACCEL : 39|8@0+ (0.08,-10.24) [-10.24|10.16] "m/s2" XXX
 SG_ SIGMA : 47|8@0+ (1,0) [0|255] "" XXX
 SG_ UNKNOWN_B6_HI : 55|4@0+ (1,0) [0|15] "" XXX
 SG_ COUNTER : 51|4@0+ (1,0) [0|15] "" XXX
 SG_ CHECKSUM : 63|8@0+ (1,0) [0|255] "" XXX

BO_ 90 RADAR_TRACK_B_10: 8 RADAR
 SG_ TRACK_ID_GEN : 7|8@0+ (1,0) [0|255] "" XXX
 SG_ UNKNOWN_B1 : 15|8@0+ (1,0) [0|255] "" XXX
 SG_ SIGMA_B : 23|8@0+ (1,0) [0|255] "" XXX
 SG_ DYN_PROP : 31|8@0+ (1,0) [0|255] "" XXX
 SG_ REL_ACCEL : 39|8@0+ (0.08,-10.24) [-10.24|10.16] "m/s2" XXX
 SG_ SIGMA : 47|8@0+ (1,0) [0|255] "" XXX
 SG_ UNKNOWN_B6_HI : 55|4@0+ (1,0) [0|15] "" XXX
 SG_ COUNTER : 51|4@0+ (1,0) [0|15] "" XXX
 SG_ CHECKSUM : 63|8@0+ (1,0) [0|255] "" XXX

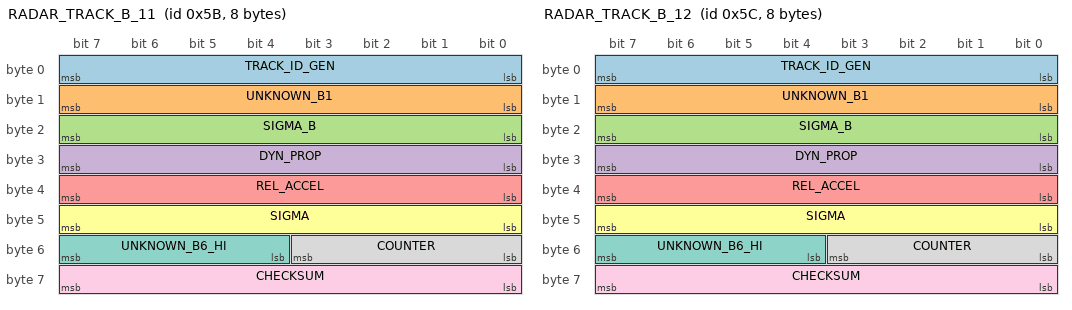
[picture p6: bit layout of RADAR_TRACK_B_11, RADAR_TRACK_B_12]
BO_ 91 RADAR_TRACK_B_11: 8 RADAR
 SG_ TRACK_ID_GEN : 7|8@0+ (1,0) [0|255] "" XXX
 SG_ UNKNOWN_B1 : 15|8@0+ (1,0) [0|255] "" XXX
 SG_ SIGMA_B : 23|8@0+ (1,0) [0|255] "" XXX
 SG_ DYN_PROP : 31|8@0+ (1,0) [0|255] "" XXX
 SG_ REL_ACCEL : 39|8@0+ (0.08,-10.24) [-10.24|10.16] "m/s2" XXX
 SG_ SIGMA : 47|8@0+ (1,0) [0|255] "" XXX
 SG_ UNKNOWN_B6_HI : 55|4@0+ (1,0) [0|15] "" XXX
 SG_ COUNTER : 51|4@0+ (1,0) [0|15] "" XXX
 SG_ CHECKSUM : 63|8@0+ (1,0) [0|255] "" XXX

BO_ 92 RADAR_TRACK_B_12: 8 RADAR
 SG_ TRACK_ID_GEN : 7|8@0+ (1,0) [0|255] "" XXX
 SG_ UNKNOWN_B1 : 15|8@0+ (1,0) [0|255] "" XXX
 SG_ SIGMA_B : 23|8@0+ (1,0) [0|255] "" XXX
 SG_ DYN_PROP : 31|8@0+ (1,0) [0|255] "" XXX
 SG_ REL_ACCEL : 39|8@0+ (0.08,-10.24) [-10.24|10.16] "m/s2" XXX
 SG_ SIGMA : 47|8@0+ (1,0) [0|255] "" XXX
 SG_ UNKNOWN_B6_HI : 55|4@0+ (1,0) [0|15] "" XXX
 SG_ COUNTER : 51|4@0+ (1,0) [0|15] "" XXX
 SG_ CHECKSUM : 63|8@0+ (1,0) [0|255] "" XXX

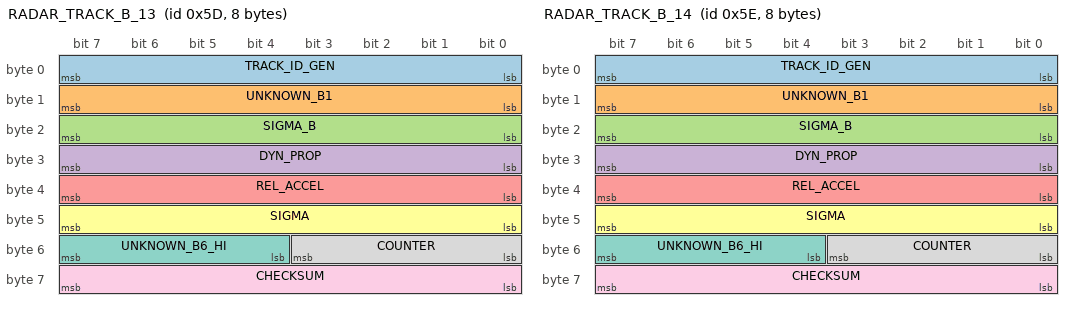
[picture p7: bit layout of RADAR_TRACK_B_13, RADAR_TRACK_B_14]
BO_ 93 RADAR_TRACK_B_13: 8 RADAR
 SG_ TRACK_ID_GEN : 7|8@0+ (1,0) [0|255] "" XXX
 SG_ UNKNOWN_B1 : 15|8@0+ (1,0) [0|255] "" XXX
 SG_ SIGMA_B : 23|8@0+ (1,0) [0|255] "" XXX
 SG_ DYN_PROP : 31|8@0+ (1,0) [0|255] "" XXX
 SG_ REL_ACCEL : 39|8@0+ (0.08,-10.24) [-10.24|10.16] "m/s2" XXX
 SG_ SIGMA : 47|8@0+ (1,0) [0|255] "" XXX
 SG_ UNKNOWN_B6_HI : 55|4@0+ (1,0) [0|15] "" XXX
 SG_ COUNTER : 51|4@0+ (1,0) [0|15] "" XXX
 SG_ CHECKSUM : 63|8@0+ (1,0) [0|255] "" XXX

BO_ 94 RADAR_TRACK_B_14: 8 RADAR
 SG_ TRACK_ID_GEN : 7|8@0+ (1,0) [0|255] "" XXX
 SG_ UNKNOWN_B1 : 15|8@0+ (1,0) [0|255] "" XXX
 SG_ SIGMA_B : 23|8@0+ (1,0) [0|255] "" XXX
 SG_ DYN_PROP : 31|8@0+ (1,0) [0|255] "" XXX
 SG_ REL_ACCEL : 39|8@0+ (0.08,-10.24) [-10.24|10.16] "m/s2" XXX
 SG_ SIGMA : 47|8@0+ (1,0) [0|255] "" XXX
 SG_ UNKNOWN_B6_HI : 55|4@0+ (1,0) [0|15] "" XXX
 SG_ COUNTER : 51|4@0+ (1,0) [0|15] "" XXX
 SG_ CHECKSUM : 63|8@0+ (1,0) [0|255] "" XXX

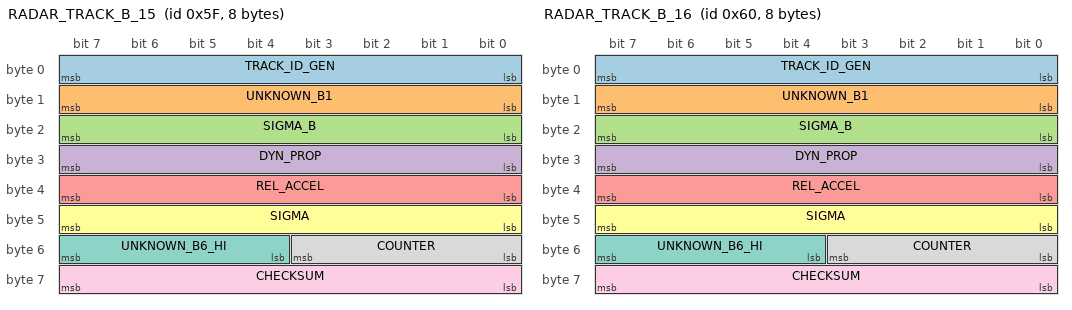
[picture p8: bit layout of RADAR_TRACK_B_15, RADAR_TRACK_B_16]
BO_ 95 RADAR_TRACK_B_15: 8 RADAR
 SG_ TRACK_ID_GEN : 7|8@0+ (1,0) [0|255] "" XXX
 SG_ UNKNOWN_B1 : 15|8@0+ (1,0) [0|255] "" XXX
 SG_ SIGMA_B : 23|8@0+ (1,0) [0|255] "" XXX
 SG_ DYN_PROP : 31|8@0+ (1,0) [0|255] "" XXX
 SG_ REL_ACCEL : 39|8@0+ (0.08,-10.24) [-10.24|10.16] "m/s2" XXX
 SG_ SIGMA : 47|8@0+ (1,0) [0|255] "" XXX
 SG_ UNKNOWN_B6_HI : 55|4@0+ (1,0) [0|15] "" XXX
 SG_ COUNTER : 51|4@0+ (1,0) [0|15] "" XXX
 SG_ CHECKSUM : 63|8@0+ (1,0) [0|255] "" XXX

BO_ 96 RADAR_TRACK_B_16: 8 RADAR
 SG_ TRACK_ID_GEN : 7|8@0+ (1,0) [0|255] "" XXX
 SG_ UNKNOWN_B1 : 15|8@0+ (1,0) [0|255] "" XXX
 SG_ SIGMA_B : 23|8@0+ (1,0) [0|255] "" XXX
 SG_ DYN_PROP : 31|8@0+ (1,0) [0|255] "" XXX
 SG_ REL_ACCEL : 39|8@0+ (0.08,-10.24) [-10.24|10.16] "m/s2" XXX
 SG_ SIGMA : 47|8@0+ (1,0) [0|255] "" XXX
 SG_ UNKNOWN_B6_HI : 55|4@0+ (1,0) [0|15] "" XXX
 SG_ COUNTER : 51|4@0+ (1,0) [0|15] "" XXX
 SG_ CHECKSUM : 63|8@0+ (1,0) [0|255] "" XXX

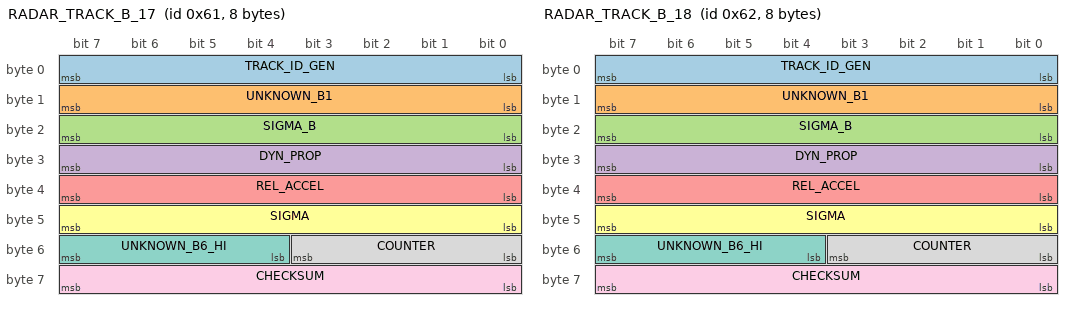
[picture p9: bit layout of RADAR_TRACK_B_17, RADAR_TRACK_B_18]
BO_ 97 RADAR_TRACK_B_17: 8 RADAR
 SG_ TRACK_ID_GEN : 7|8@0+ (1,0) [0|255] "" XXX
 SG_ UNKNOWN_B1 : 15|8@0+ (1,0) [0|255] "" XXX
 SG_ SIGMA_B : 23|8@0+ (1,0) [0|255] "" XXX
 SG_ DYN_PROP : 31|8@0+ (1,0) [0|255] "" XXX
 SG_ REL_ACCEL : 39|8@0+ (0.08,-10.24) [-10.24|10.16] "m/s2" XXX
 SG_ SIGMA : 47|8@0+ (1,0) [0|255] "" XXX
 SG_ UNKNOWN_B6_HI : 55|4@0+ (1,0) [0|15] "" XXX
 SG_ COUNTER : 51|4@0+ (1,0) [0|15] "" XXX
 SG_ CHECKSUM : 63|8@0+ (1,0) [0|255] "" XXX

BO_ 98 RADAR_TRACK_B_18: 8 RADAR
 SG_ TRACK_ID_GEN : 7|8@0+ (1,0) [0|255] "" XXX
 SG_ UNKNOWN_B1 : 15|8@0+ (1,0) [0|255] "" XXX
 SG_ SIGMA_B : 23|8@0+ (1,0) [0|255] "" XXX
 SG_ DYN_PROP : 31|8@0+ (1,0) [0|255] "" XXX
 SG_ REL_ACCEL : 39|8@0+ (0.08,-10.24) [-10.24|10.16] "m/s2" XXX
 SG_ SIGMA : 47|8@0+ (1,0) [0|255] "" XXX
 SG_ UNKNOWN_B6_HI : 55|4@0+ (1,0) [0|15] "" XXX
 SG_ COUNTER : 51|4@0+ (1,0) [0|15] "" XXX
 SG_ CHECKSUM : 63|8@0+ (1,0) [0|255] "" XXX

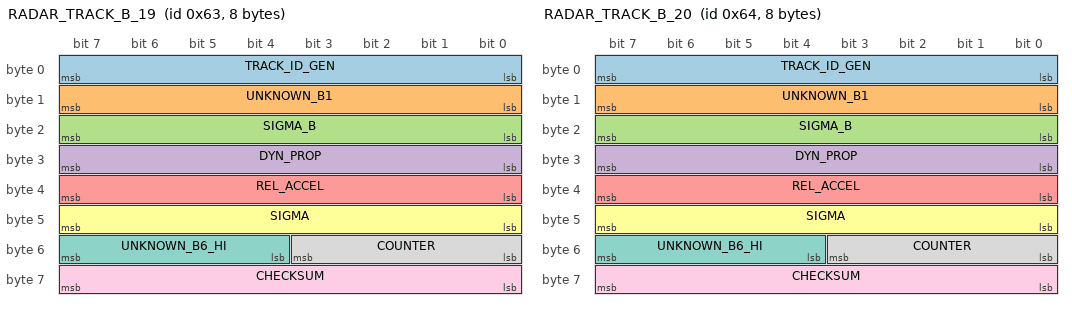
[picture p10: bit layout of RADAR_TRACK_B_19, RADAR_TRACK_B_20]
BO_ 99 RADAR_TRACK_B_19: 8 RADAR
 SG_ TRACK_ID_GEN : 7|8@0+ (1,0) [0|255] "" XXX
 SG_ UNKNOWN_B1 : 15|8@0+ (1,0) [0|255] "" XXX
 SG_ SIGMA_B : 23|8@0+ (1,0) [0|255] "" XXX
 SG_ DYN_PROP : 31|8@0+ (1,0) [0|255] "" XXX
 SG_ REL_ACCEL : 39|8@0+ (0.08,-10.24) [-10.24|10.16] "m/s2" XXX
 SG_ SIGMA : 47|8@0+ (1,0) [0|255] "" XXX
 SG_ UNKNOWN_B6_HI : 55|4@0+ (1,0) [0|15] "" XXX
 SG_ COUNTER : 51|4@0+ (1,0) [0|15] "" XXX
 SG_ CHECKSUM : 63|8@0+ (1,0) [0|255] "" XXX

BO_ 100 RADAR_TRACK_B_20: 8 RADAR
 SG_ TRACK_ID_GEN : 7|8@0+ (1,0) [0|255] "" XXX
 SG_ UNKNOWN_B1 : 15|8@0+ (1,0) [0|255] "" XXX
 SG_ SIGMA_B : 23|8@0+ (1,0) [0|255] "" XXX
 SG_ DYN_PROP : 31|8@0+ (1,0) [0|255] "" XXX
 SG_ REL_ACCEL : 39|8@0+ (0.08,-10.24) [-10.24|10.16] "m/s2" XXX
 SG_ SIGMA : 47|8@0+ (1,0) [0|255] "" XXX
 SG_ UNKNOWN_B6_HI : 55|4@0+ (1,0) [0|15] "" XXX
 SG_ COUNTER : 51|4@0+ (1,0) [0|15] "" XXX
 SG_ CHECKSUM : 63|8@0+ (1,0) [0|255] "" XXX

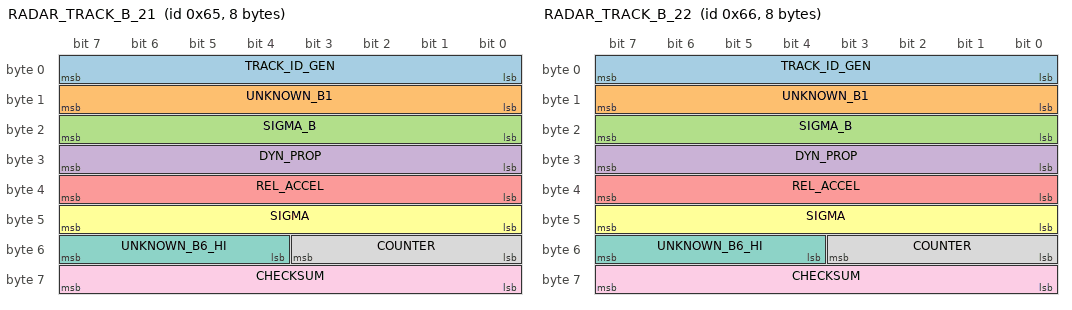
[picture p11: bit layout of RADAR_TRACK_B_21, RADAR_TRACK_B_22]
BO_ 101 RADAR_TRACK_B_21: 8 RADAR
 SG_ TRACK_ID_GEN : 7|8@0+ (1,0) [0|255] "" XXX
 SG_ UNKNOWN_B1 : 15|8@0+ (1,0) [0|255] "" XXX
 SG_ SIGMA_B : 23|8@0+ (1,0) [0|255] "" XXX
 SG_ DYN_PROP : 31|8@0+ (1,0) [0|255] "" XXX
 SG_ REL_ACCEL : 39|8@0+ (0.08,-10.24) [-10.24|10.16] "m/s2" XXX
 SG_ SIGMA : 47|8@0+ (1,0) [0|255] "" XXX
 SG_ UNKNOWN_B6_HI : 55|4@0+ (1,0) [0|15] "" XXX
 SG_ COUNTER : 51|4@0+ (1,0) [0|15] "" XXX
 SG_ CHECKSUM : 63|8@0+ (1,0) [0|255] "" XXX

BO_ 102 RADAR_TRACK_B_22: 8 RADAR
 SG_ TRACK_ID_GEN : 7|8@0+ (1,0) [0|255] "" XXX
 SG_ UNKNOWN_B1 : 15|8@0+ (1,0) [0|255] "" XXX
 SG_ SIGMA_B : 23|8@0+ (1,0) [0|255] "" XXX
 SG_ DYN_PROP : 31|8@0+ (1,0) [0|255] "" XXX
 SG_ REL_ACCEL : 39|8@0+ (0.08,-10.24) [-10.24|10.16] "m/s2" XXX
 SG_ SIGMA : 47|8@0+ (1,0) [0|255] "" XXX
 SG_ UNKNOWN_B6_HI : 55|4@0+ (1,0) [0|15] "" XXX
 SG_ COUNTER : 51|4@0+ (1,0) [0|15] "" XXX
 SG_ CHECKSUM : 63|8@0+ (1,0) [0|255] "" XXX

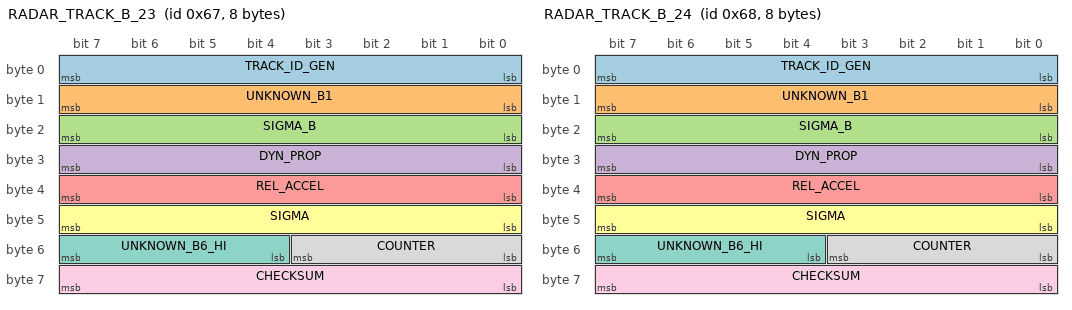
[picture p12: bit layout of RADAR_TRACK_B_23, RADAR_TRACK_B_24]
BO_ 103 RADAR_TRACK_B_23: 8 RADAR
 SG_ TRACK_ID_GEN : 7|8@0+ (1,0) [0|255] "" XXX
 SG_ UNKNOWN_B1 : 15|8@0+ (1,0) [0|255] "" XXX
 SG_ SIGMA_B : 23|8@0+ (1,0) [0|255] "" XXX
 SG_ DYN_PROP : 31|8@0+ (1,0) [0|255] "" XXX
 SG_ REL_ACCEL : 39|8@0+ (0.08,-10.24) [-10.24|10.16] "m/s2" XXX
 SG_ SIGMA : 47|8@0+ (1,0) [0|255] "" XXX
 SG_ UNKNOWN_B6_HI : 55|4@0+ (1,0) [0|15] "" XXX
 SG_ COUNTER : 51|4@0+ (1,0) [0|15] "" XXX
 SG_ CHECKSUM : 63|8@0+ (1,0) [0|255] "" XXX

BO_ 104 RADAR_TRACK_B_24: 8 RADAR
 SG_ TRACK_ID_GEN : 7|8@0+ (1,0) [0|255] "" XXX
 SG_ UNKNOWN_B1 : 15|8@0+ (1,0) [0|255] "" XXX
 SG_ SIGMA_B : 23|8@0+ (1,0) [0|255] "" XXX
 SG_ DYN_PROP : 31|8@0+ (1,0) [0|255] "" XXX
 SG_ REL_ACCEL : 39|8@0+ (0.08,-10.24) [-10.24|10.16] "m/s2" XXX
 SG_ SIGMA : 47|8@0+ (1,0) [0|255] "" XXX
 SG_ UNKNOWN_B6_HI : 55|4@0+ (1,0) [0|15] "" XXX
 SG_ COUNTER : 51|4@0+ (1,0) [0|15] "" XXX
 SG_ CHECKSUM : 63|8@0+ (1,0) [0|255] "" XXX

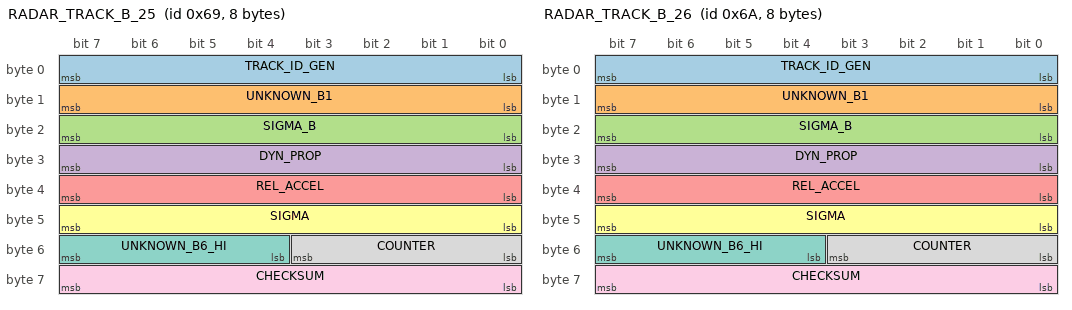
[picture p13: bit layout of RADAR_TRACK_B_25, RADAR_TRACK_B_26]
BO_ 105 RADAR_TRACK_B_25: 8 RADAR
 SG_ TRACK_ID_GEN : 7|8@0+ (1,0) [0|255] "" XXX
 SG_ UNKNOWN_B1 : 15|8@0+ (1,0) [0|255] "" XXX
 SG_ SIGMA_B : 23|8@0+ (1,0) [0|255] "" XXX
 SG_ DYN_PROP : 31|8@0+ (1,0) [0|255] "" XXX
 SG_ REL_ACCEL : 39|8@0+ (0.08,-10.24) [-10.24|10.16] "m/s2" XXX
 SG_ SIGMA : 47|8@0+ (1,0) [0|255] "" XXX
 SG_ UNKNOWN_B6_HI : 55|4@0+ (1,0) [0|15] "" XXX
 SG_ COUNTER : 51|4@0+ (1,0) [0|15] "" XXX
 SG_ CHECKSUM : 63|8@0+ (1,0) [0|255] "" XXX

BO_ 106 RADAR_TRACK_B_26: 8 RADAR
 SG_ TRACK_ID_GEN : 7|8@0+ (1,0) [0|255] "" XXX
 SG_ UNKNOWN_B1 : 15|8@0+ (1,0) [0|255] "" XXX
 SG_ SIGMA_B : 23|8@0+ (1,0) [0|255] "" XXX
 SG_ DYN_PROP : 31|8@0+ (1,0) [0|255] "" XXX
 SG_ REL_ACCEL : 39|8@0+ (0.08,-10.24) [-10.24|10.16] "m/s2" XXX
 SG_ SIGMA : 47|8@0+ (1,0) [0|255] "" XXX
 SG_ UNKNOWN_B6_HI : 55|4@0+ (1,0) [0|15] "" XXX
 SG_ COUNTER : 51|4@0+ (1,0) [0|15] "" XXX
 SG_ CHECKSUM : 63|8@0+ (1,0) [0|255] "" XXX

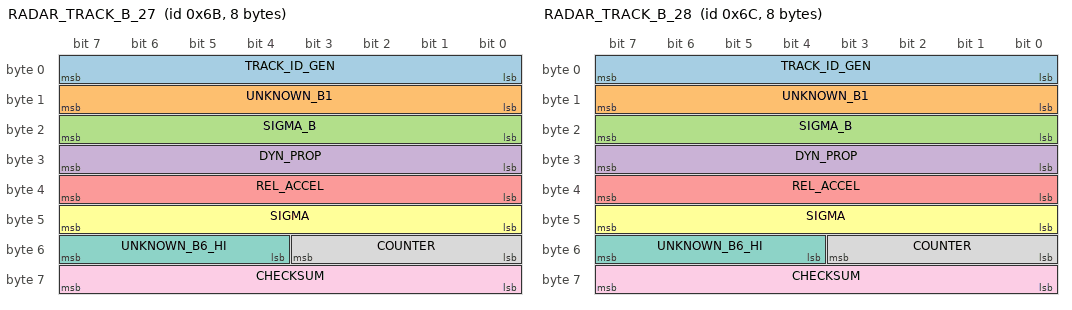
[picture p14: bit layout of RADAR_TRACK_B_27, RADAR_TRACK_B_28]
BO_ 107 RADAR_TRACK_B_27: 8 RADAR
 SG_ TRACK_ID_GEN : 7|8@0+ (1,0) [0|255] "" XXX
 SG_ UNKNOWN_B1 : 15|8@0+ (1,0) [0|255] "" XXX
 SG_ SIGMA_B : 23|8@0+ (1,0) [0|255] "" XXX
 SG_ DYN_PROP : 31|8@0+ (1,0) [0|255] "" XXX
 SG_ REL_ACCEL : 39|8@0+ (0.08,-10.24) [-10.24|10.16] "m/s2" XXX
 SG_ SIGMA : 47|8@0+ (1,0) [0|255] "" XXX
 SG_ UNKNOWN_B6_HI : 55|4@0+ (1,0) [0|15] "" XXX
 SG_ COUNTER : 51|4@0+ (1,0) [0|15] "" XXX
 SG_ CHECKSUM : 63|8@0+ (1,0) [0|255] "" XXX

BO_ 108 RADAR_TRACK_B_28: 8 RADAR
 SG_ TRACK_ID_GEN : 7|8@0+ (1,0) [0|255] "" XXX
 SG_ UNKNOWN_B1 : 15|8@0+ (1,0) [0|255] "" XXX
 SG_ SIGMA_B : 23|8@0+ (1,0) [0|255] "" XXX
 SG_ DYN_PROP : 31|8@0+ (1,0) [0|255] "" XXX
 SG_ REL_ACCEL : 39|8@0+ (0.08,-10.24) [-10.24|10.16] "m/s2" XXX
 SG_ SIGMA : 47|8@0+ (1,0) [0|255] "" XXX
 SG_ UNKNOWN_B6_HI : 55|4@0+ (1,0) [0|15] "" XXX
 SG_ COUNTER : 51|4@0+ (1,0) [0|15] "" XXX
 SG_ CHECKSUM : 63|8@0+ (1,0) [0|255] "" XXX

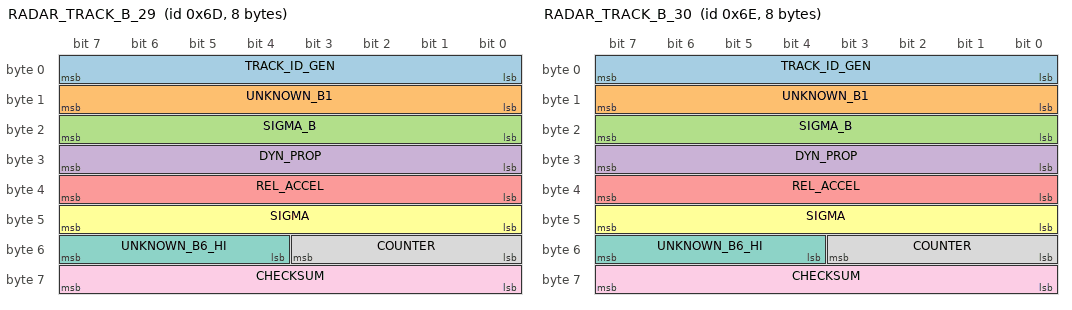
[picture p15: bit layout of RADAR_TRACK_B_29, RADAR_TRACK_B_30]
BO_ 109 RADAR_TRACK_B_29: 8 RADAR
 SG_ TRACK_ID_GEN : 7|8@0+ (1,0) [0|255] "" XXX
 SG_ UNKNOWN_B1 : 15|8@0+ (1,0) [0|255] "" XXX
 SG_ SIGMA_B : 23|8@0+ (1,0) [0|255] "" XXX
 SG_ DYN_PROP : 31|8@0+ (1,0) [0|255] "" XXX
 SG_ REL_ACCEL : 39|8@0+ (0.08,-10.24) [-10.24|10.16] "m/s2" XXX
 SG_ SIGMA : 47|8@0+ (1,0) [0|255] "" XXX
 SG_ UNKNOWN_B6_HI : 55|4@0+ (1,0) [0|15] "" XXX
 SG_ COUNTER : 51|4@0+ (1,0) [0|15] "" XXX
 SG_ CHECKSUM : 63|8@0+ (1,0) [0|255] "" XXX

BO_ 110 RADAR_TRACK_B_30: 8 RADAR
 SG_ TRACK_ID_GEN : 7|8@0+ (1,0) [0|255] "" XXX
 SG_ UNKNOWN_B1 : 15|8@0+ (1,0) [0|255] "" XXX
 SG_ SIGMA_B : 23|8@0+ (1,0) [0|255] "" XXX
 SG_ DYN_PROP : 31|8@0+ (1,0) [0|255] "" XXX
 SG_ REL_ACCEL : 39|8@0+ (0.08,-10.24) [-10.24|10.16] "m/s2" XXX
 SG_ SIGMA : 47|8@0+ (1,0) [0|255] "" XXX
 SG_ UNKNOWN_B6_HI : 55|4@0+ (1,0) [0|15] "" XXX
 SG_ COUNTER : 51|4@0+ (1,0) [0|15] "" XXX
 SG_ CHECKSUM : 63|8@0+ (1,0) [0|255] "" XXX

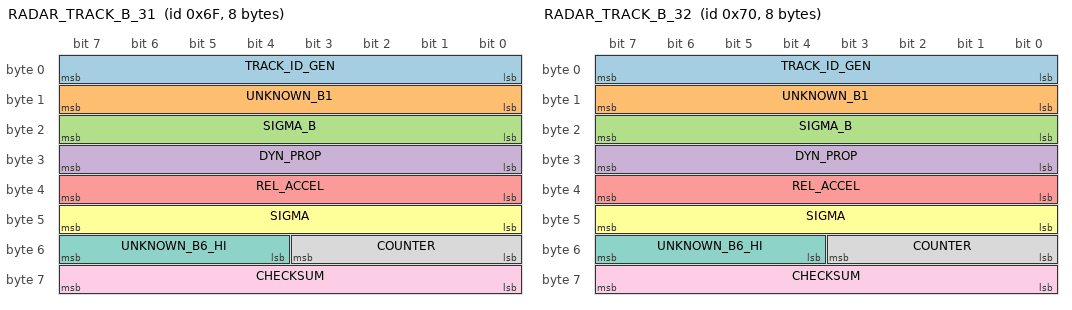
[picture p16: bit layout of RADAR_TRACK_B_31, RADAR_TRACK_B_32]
BO_ 111 RADAR_TRACK_B_31: 8 RADAR
 SG_ TRACK_ID_GEN : 7|8@0+ (1,0) [0|255] "" XXX
 SG_ UNKNOWN_B1 : 15|8@0+ (1,0) [0|255] "" XXX
 SG_ SIGMA_B : 23|8@0+ (1,0) [0|255] "" XXX
 SG_ DYN_PROP : 31|8@0+ (1,0) [0|255] "" XXX
 SG_ REL_ACCEL : 39|8@0+ (0.08,-10.24) [-10.24|10.16] "m/s2" XXX
 SG_ SIGMA : 47|8@0+ (1,0) [0|255] "" XXX
 SG_ UNKNOWN_B6_HI : 55|4@0+ (1,0) [0|15] "" XXX
 SG_ COUNTER : 51|4@0+ (1,0) [0|15] "" XXX
 SG_ CHECKSUM : 63|8@0+ (1,0) [0|255] "" XXX

BO_ 112 RADAR_TRACK_B_32: 8 RADAR
 SG_ TRACK_ID_GEN : 7|8@0+ (1,0) [0|255] "" XXX
 SG_ UNKNOWN_B1 : 15|8@0+ (1,0) [0|255] "" XXX
 SG_ SIGMA_B : 23|8@0+ (1,0) [0|255] "" XXX
 SG_ DYN_PROP : 31|8@0+ (1,0) [0|255] "" XXX
 SG_ REL_ACCEL : 39|8@0+ (0.08,-10.24) [-10.24|10.16] "m/s2" XXX
 SG_ SIGMA : 47|8@0+ (1,0) [0|255] "" XXX
 SG_ UNKNOWN_B6_HI : 55|4@0+ (1,0) [0|15] "" XXX
 SG_ COUNTER : 51|4@0+ (1,0) [0|15] "" XXX
 SG_ CHECKSUM : 63|8@0+ (1,0) [0|255] "" XXX

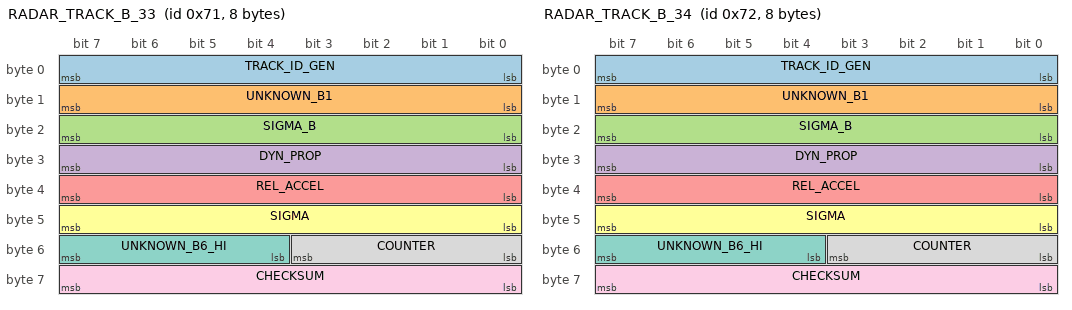
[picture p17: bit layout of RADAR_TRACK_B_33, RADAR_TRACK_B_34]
BO_ 113 RADAR_TRACK_B_33: 8 RADAR
 SG_ TRACK_ID_GEN : 7|8@0+ (1,0) [0|255] "" XXX
 SG_ UNKNOWN_B1 : 15|8@0+ (1,0) [0|255] "" XXX
 SG_ SIGMA_B : 23|8@0+ (1,0) [0|255] "" XXX
 SG_ DYN_PROP : 31|8@0+ (1,0) [0|255] "" XXX
 SG_ REL_ACCEL : 39|8@0+ (0.08,-10.24) [-10.24|10.16] "m/s2" XXX
 SG_ SIGMA : 47|8@0+ (1,0) [0|255] "" XXX
 SG_ UNKNOWN_B6_HI : 55|4@0+ (1,0) [0|15] "" XXX
 SG_ COUNTER : 51|4@0+ (1,0) [0|15] "" XXX
 SG_ CHECKSUM : 63|8@0+ (1,0) [0|255] "" XXX

BO_ 114 RADAR_TRACK_B_34: 8 RADAR
 SG_ TRACK_ID_GEN : 7|8@0+ (1,0) [0|255] "" XXX
 SG_ UNKNOWN_B1 : 15|8@0+ (1,0) [0|255] "" XXX
 SG_ SIGMA_B : 23|8@0+ (1,0) [0|255] "" XXX
 SG_ DYN_PROP : 31|8@0+ (1,0) [0|255] "" XXX
 SG_ REL_ACCEL : 39|8@0+ (0.08,-10.24) [-10.24|10.16] "m/s2" XXX
 SG_ SIGMA : 47|8@0+ (1,0) [0|255] "" XXX
 SG_ UNKNOWN_B6_HI : 55|4@0+ (1,0) [0|15] "" XXX
 SG_ COUNTER : 51|4@0+ (1,0) [0|15] "" XXX
 SG_ CHECKSUM : 63|8@0+ (1,0) [0|255] "" XXX

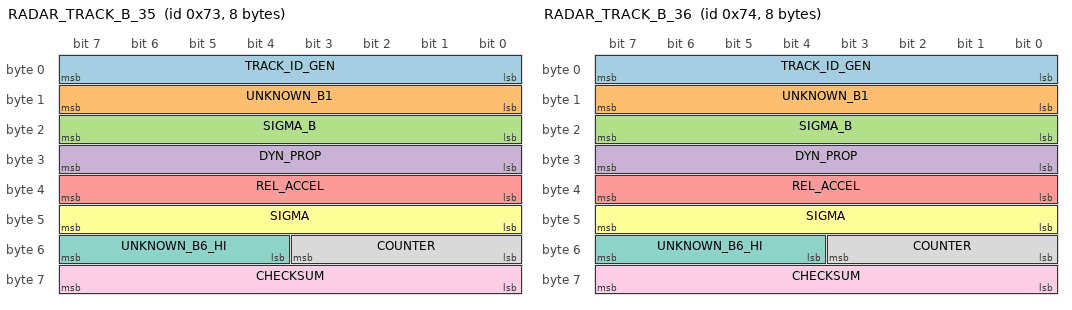
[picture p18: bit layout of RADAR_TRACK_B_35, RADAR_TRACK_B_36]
BO_ 115 RADAR_TRACK_B_35: 8 RADAR
 SG_ TRACK_ID_GEN : 7|8@0+ (1,0) [0|255] "" XXX
 SG_ UNKNOWN_B1 : 15|8@0+ (1,0) [0|255] "" XXX
 SG_ SIGMA_B : 23|8@0+ (1,0) [0|255] "" XXX
 SG_ DYN_PROP : 31|8@0+ (1,0) [0|255] "" XXX
 SG_ REL_ACCEL : 39|8@0+ (0.08,-10.24) [-10.24|10.16] "m/s2" XXX
 SG_ SIGMA : 47|8@0+ (1,0) [0|255] "" XXX
 SG_ UNKNOWN_B6_HI : 55|4@0+ (1,0) [0|15] "" XXX
 SG_ COUNTER : 51|4@0+ (1,0) [0|15] "" XXX
 SG_ CHECKSUM : 63|8@0+ (1,0) [0|255] "" XXX

BO_ 116 RADAR_TRACK_B_36: 8 RADAR
 SG_ TRACK_ID_GEN : 7|8@0+ (1,0) [0|255] "" XXX
 SG_ UNKNOWN_B1 : 15|8@0+ (1,0) [0|255] "" XXX
 SG_ SIGMA_B : 23|8@0+ (1,0) [0|255] "" XXX
 SG_ DYN_PROP : 31|8@0+ (1,0) [0|255] "" XXX
 SG_ REL_ACCEL : 39|8@0+ (0.08,-10.24) [-10.24|10.16] "m/s2" XXX
 SG_ SIGMA : 47|8@0+ (1,0) [0|255] "" XXX
 SG_ UNKNOWN_B6_HI : 55|4@0+ (1,0) [0|15] "" XXX
 SG_ COUNTER : 51|4@0+ (1,0) [0|15] "" XXX
 SG_ CHECKSUM : 63|8@0+ (1,0) [0|255] "" XXX

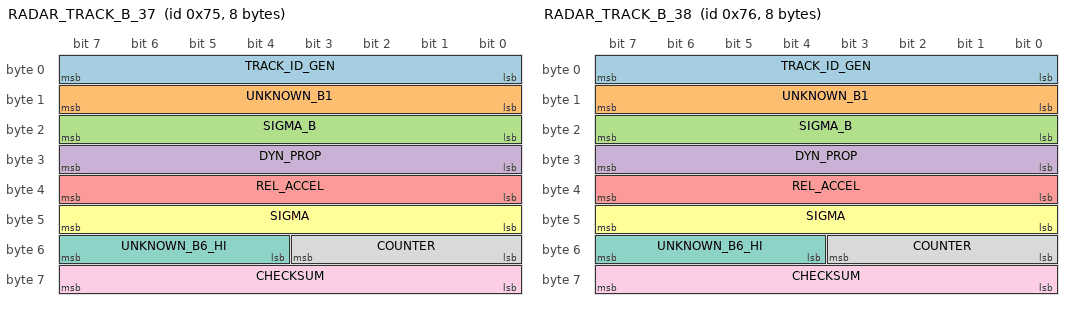
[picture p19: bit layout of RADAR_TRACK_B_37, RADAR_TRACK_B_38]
BO_ 117 RADAR_TRACK_B_37: 8 RADAR
 SG_ TRACK_ID_GEN : 7|8@0+ (1,0) [0|255] "" XXX
 SG_ UNKNOWN_B1 : 15|8@0+ (1,0) [0|255] "" XXX
 SG_ SIGMA_B : 23|8@0+ (1,0) [0|255] "" XXX
 SG_ DYN_PROP : 31|8@0+ (1,0) [0|255] "" XXX
 SG_ REL_ACCEL : 39|8@0+ (0.08,-10.24) [-10.24|10.16] "m/s2" XXX
 SG_ SIGMA : 47|8@0+ (1,0) [0|255] "" XXX
 SG_ UNKNOWN_B6_HI : 55|4@0+ (1,0) [0|15] "" XXX
 SG_ COUNTER : 51|4@0+ (1,0) [0|15] "" XXX
 SG_ CHECKSUM : 63|8@0+ (1,0) [0|255] "" XXX

BO_ 118 RADAR_TRACK_B_38: 8 RADAR
 SG_ TRACK_ID_GEN : 7|8@0+ (1,0) [0|255] "" XXX
 SG_ UNKNOWN_B1 : 15|8@0+ (1,0) [0|255] "" XXX
 SG_ SIGMA_B : 23|8@0+ (1,0) [0|255] "" XXX
 SG_ DYN_PROP : 31|8@0+ (1,0) [0|255] "" XXX
 SG_ REL_ACCEL : 39|8@0+ (0.08,-10.24) [-10.24|10.16] "m/s2" XXX
 SG_ SIGMA : 47|8@0+ (1,0) [0|255] "" XXX
 SG_ UNKNOWN_B6_HI : 55|4@0+ (1,0) [0|15] "" XXX
 SG_ COUNTER : 51|4@0+ (1,0) [0|15] "" XXX
 SG_ CHECKSUM : 63|8@0+ (1,0) [0|255] "" XXX

BO_ 119 RADAR_TRACK_B_39: 8 RADAR
 SG_ TRACK_ID_GEN : 7|8@0+ (1,0) [0|255] "" XXX
 SG_ UNKNOWN_B1 : 15|8@0+ (1,0) [0|255] "" XXX
 SG_ SIGMA_B : 23|8@0+ (1,0) [0|255] "" XXX
 SG_ DYN_PROP : 31|8@0+ (1,0) [0|255] "" XXX
 SG_ REL_ACCEL : 39|8@0+ (0.08,-10.24) [-10.24|10.16] "m/s2" XXX
 SG_ SIGMA : 47|8@0+ (1,0) [0|255] "" XXX
 SG_ UNKNOWN_B6_HI : 55|4@0+ (1,0) [0|15] "" XXX
 SG_ COUNTER : 51|4@0+ (1,0) [0|15] "" XXX
 SG_ CHECKSUM : 63|8@0+ (1,0) [0|255] "" XXX

CM_ "Geely Binyue - Continental ARS410(ARS4-B) 前雷达, Bus1 (雷达直出, 未经融合)";
CM_ "逆向 2026-07-19/21, 车型/123 全量CSV(700万+报文) 交叉验证. 详见 geely_ARS410_逆向总结.md";
CM_ BO_ 128 "车->雷达 本车运动+雷达状态, 55ms. HostSpeed/Host_Yaw 是雷达做静止物补偿所必需";
CM_ SG_ 128 FRS_Host_Yaw "零点1024=2^10. 与车身0x130偏航率回归斜率1.00(r=0.997)";
CM_ SG_ 128 FRS_HostSpeed "★实车 vs openpilot vEgo(轮速) r=+0.99998 斜率0.9936 截距0.125m/s. 该0.64%差异更可能是轮速(轮胎尺寸)标定误差而非雷达";
CM_ SG_ 128 FRS_Msg_CheckSum "CRC-8/AUTOSAR poly=0x2F init=0xFF xorout=0xFF over byte0-6. ★2026-07-21实车验证: 277万帧(A组136.9万/B组136.9万/0x080 3.4万) 100.0000% 精确匹配, 零例外 —— 同时证明字节序/报文边界正确, 且byte7确为CRC(旧DBC说的AZIMUTH在此位置是错的)";
CM_ "目标: 槽k 由两条报文组成 A=0x20+k, B=0x50+k. 40槽几乎永远占满, 但66-76%航迹<0.5s是杂波";
CM_ SG_ 32 DISTANCE "= 0.98*(b3<<8|b4)/256 - 3.4. 三重验证: 皮尺<0.1m + 运动学自洽斜率1.01 + 独立摄像头r=0.999偏差-0.04m";
CM_ SG_ 32 REL_SPEED "= (b0-127.6)/1.27. 负=接近. 六录制 r=0.999 残差0.3-0.6m/s (静止物vRel=-vEgo验证)";
CM_ SG_ 32 LAT_SPEED "横向速度. 2026-07-21实车88.8万帧标定(真值=-w*dRel, w取自0x080 FRS_Host_Yaw不依赖steerRatio): r=+0.994, 零点=128.00(14.9万条直行样本 std 0.575). scale按距离段 2-15m:1.658 / 15-30:1.434 / 30-50:1.354 / 50-150:1.311 —— 漂移是因真值应用纵向距离x=R*cosθ而非斜距R(当时方位角还没解出); 趋势收敛到~1.27~1.30 => 与纵向REL_SPEED共用同一量化1.27 counts/(m/s)";
CM_ SG_ 32 LAT_POS "横向位置 = byte1[4:0]+byte2, BE(bit12|13), *0.015625-64, [负右/正左, m]. 2026-08-20订正: 早先以为报文没有横向位置是错的(几何法把纵向XPos当径向R造错了真值). 官方Continental FRS DBC核对+实车4重验证: ①前车YPos≈0 ②静止物按|YPos|分档闭合率恒=满vEgo(证byte3-4是纵向非径向) ③d(YPos)/dt对YVelRel(byte5)斜率1.00 ④CANParser逐帧一致. radard靠它做视觉-雷达横向匹配(同距离区分在道前车vs路边物), 见opendbc/car/geely/radar_interface.py文件头";
CM_ SG_ 32 UNKNOWN_B1 "未解. 是物理量(轨迹内lag-1自相关0.80), 轨迹内 vs |vRel| r=+0.38";
CM_ SG_ 32 UNKNOWN_B2 "未解. 是物理量(自相关0.876) 但与距离/速度/加速度/sigma全部无关";
CM_ SG_ 80 TRACK_ID_GEN "= 槽号 + 40*代次n. b0 mod 40 == 槽号(189万条100%). n变=槽位换了新目标(实测99.7%) => (槽号,n)是真航迹ID";
CM_ SG_ 80 DYN_PROP "动静分类, 【单向蕴含+有速度门槛】. 2026-07-21实车10.8万样本按对地速度分档: 0-1m/s中位43(>=100仅0.2%) / 1-3中位44(9.9%) / 3-6中位48(15.4%) / 6-10中位120(73%) / 10-20中位127(56.5%). ★正确用法: 30~60 => 静止 可靠(误判率2.0%); >=100 => 移动 只有64%可靠, 且雷达要目标>6m/s才肯标移动, 1~6m/s慢车仍编在30~60区. ★不可反用: 30~60 不等于 一定静止. (旧注释写的 112~127=移动车 已证实只对一半)";
CM_ SG_ 80 REL_ACCEL "= (b4-128)/12.5. 五录制 r=0.85-0.95 残差0.17-0.33 (确认静止物 aRel=-a_ego验证)";
CM_ SG_ 80 SIGMA "★不是单一8位数, 实为 [高6位=不确定度0~63][低2位=标志]★. 实测低2位 86.5%恒为0b11(这就是旧注释说'取值全是4n+3'的真相); 高6位取值集中2~7(3:42% 4:16% 5:10%), 随航迹成熟递减=质量指标, 越小越可信. 用高6位重看: 第1帧5 ->3帧4 ->8帧3收敛; 目标丢失前飙到7";
CM_ SG_ 32 COUNTER "★实车验证: 逐帧+1(mod16), A组1368932/1368938 B组1368943/1368945 0x080 34223/34223 = 100.00%★";
CM_ SG_ 128 FRS_TimeStamp "★实车验证: 对真实时间回归 r=+0.99999984, 实测 1.00786 s/count(DBC写1.0077, 差0.02%). 注 1.00786≈129/128=1.0078125 => 雷达内部时钟是 1/128 秒 tick";
CM_ SG_ 128 FRS_Latency "★实车: 中位58ms 范围36~106ms, 符合雷达处理时延量级";
CM_ SG_ 128 FRS_Msg_AliveCounter "★实车验证: 逐帧+1(mod16) 34223/34223 = 100.00%";
